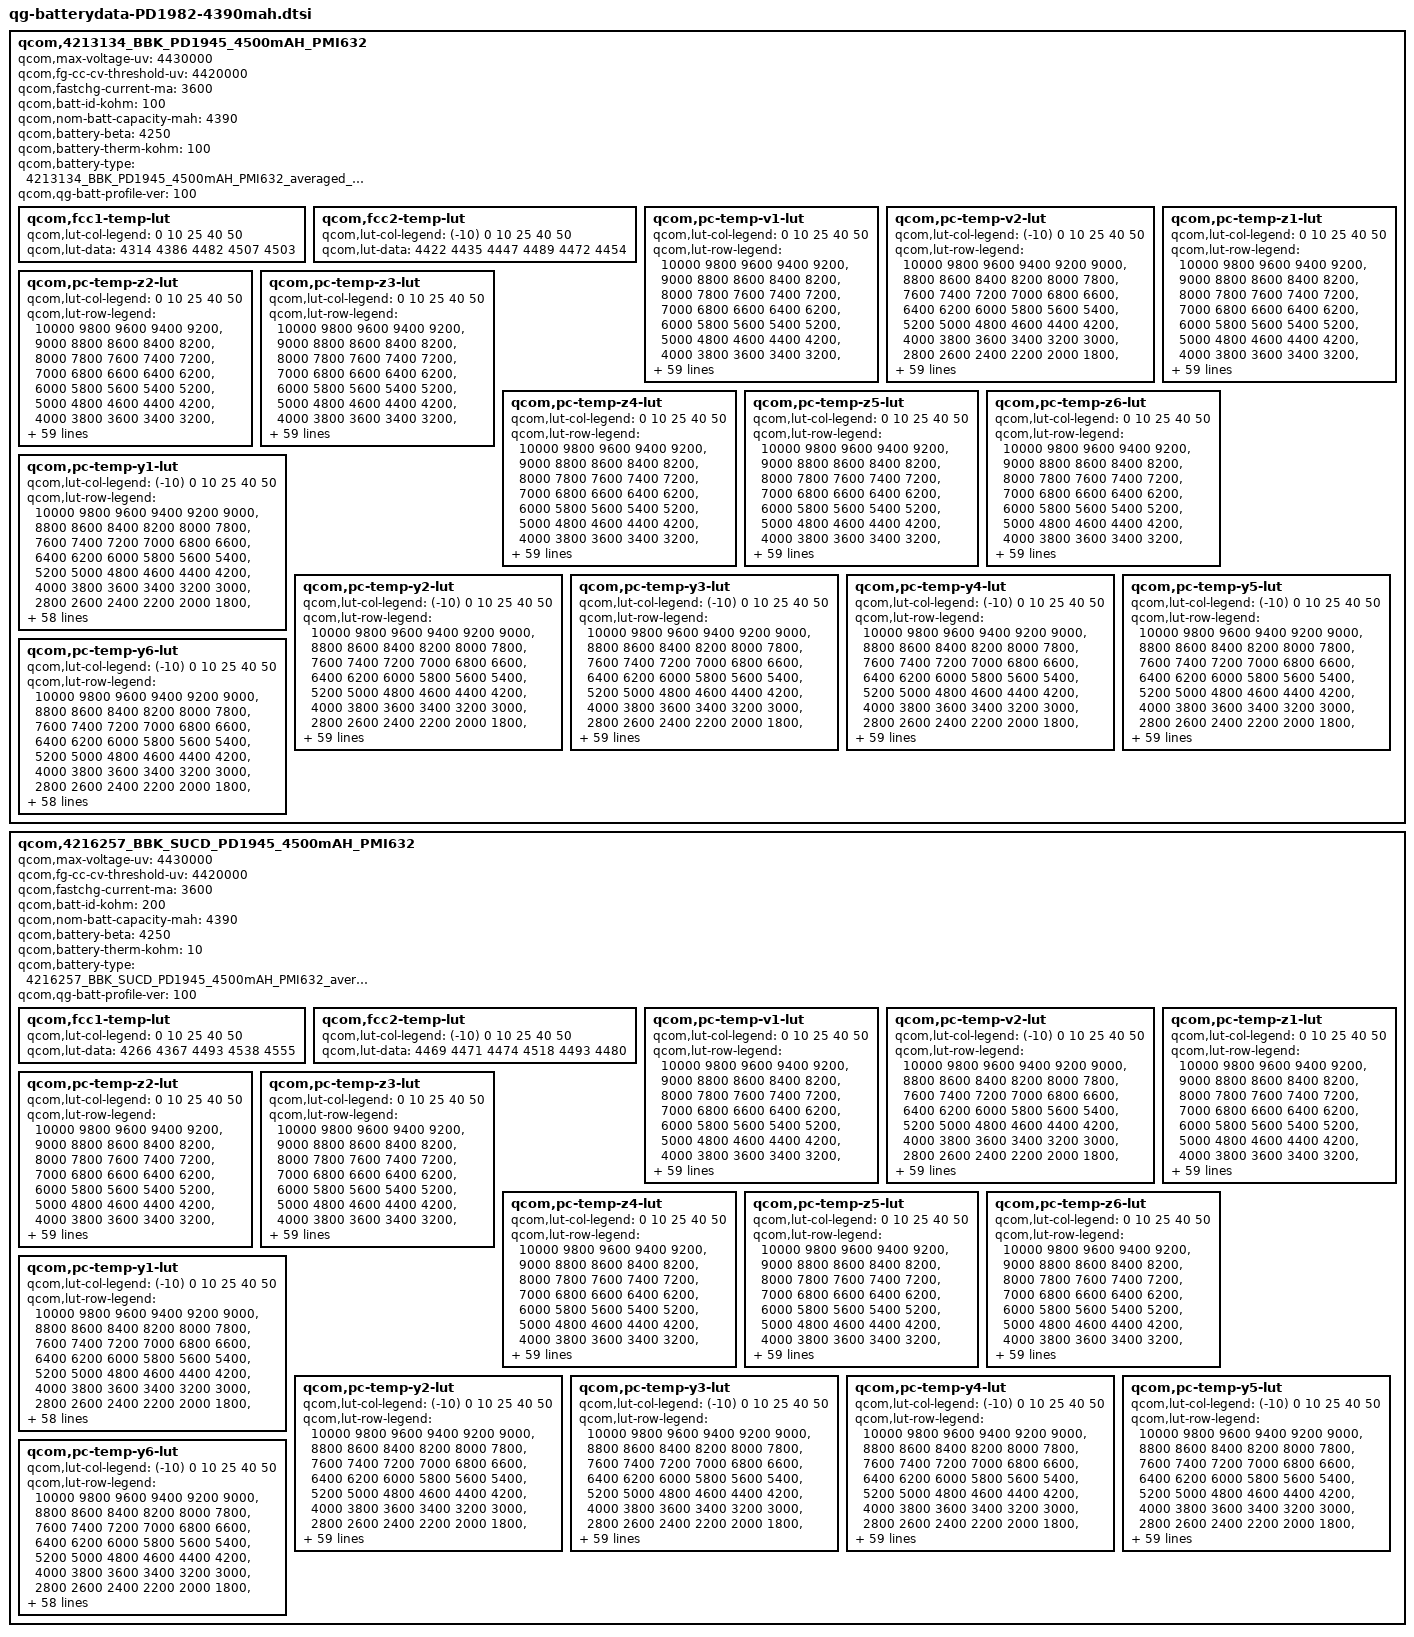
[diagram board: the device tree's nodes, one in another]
/*
 * Copyright (c) 2018, The Linux Foundation. All rights reserved.
 *
 * This program is free software; you can redistribute it and/or modify
 * it under the terms of the GNU General Public License version 2 and
 * only version 2 as published by the Free Software Foundation.
 *
 * This program is distributed in the hope that it will be useful,
 * but WITHOUT ANY WARRANTY; without even the implied warranty of
 * MERCHANTABILITY or FITNESS FOR A PARTICULAR PURPOSE.  See the
 * GNU General Public License for more details.
 */

qcom,4213134_BBK_PD1945_4500mAH_PMI632 {
    /* 4213134_BBK_PD1945_4500mAH_PMI632_averaged_MasterSlave_Sep23th2019 */
    qcom,max-voltage-uv = <4430000>;
    qcom,fg-cc-cv-threshold-uv = <4420000>;
    qcom,fastchg-current-ma = <3600>;
    qcom,batt-id-kohm = <100>;
    qcom,nom-batt-capacity-mah = <4390>;/*min value*/
    qcom,battery-beta = <4250>;
    qcom,battery-therm-kohm = <100>;
    qcom,battery-type = "4213134_BBK_PD1945_4500mAH_PMI632_averaged_MasterSlave_Sep23th2019:batid(20)";
    qcom,qg-batt-profile-ver = <100>;

	qcom,fcc1-temp-lut {
		qcom,lut-col-legend = <0 10 25 40 50>;
		qcom,lut-data = <4314 4386 4482 4507 4503>;
	};

	qcom,fcc2-temp-lut {
		qcom,lut-col-legend = <(-10) 0 10 25 40 50>;
		qcom,lut-data = <4422 4435 4447 4489 4472 4454>;
	};

	qcom,pc-temp-v1-lut {
		qcom,lut-col-legend = <0 10 25 40 50>;
		qcom,lut-row-legend = <10000 9800 9600 9400 9200>,
			<9000 8800 8600 8400 8200>,
			<8000 7800 7600 7400 7200>,
			<7000 6800 6600 6400 6200>,
			<6000 5800 5600 5400 5200>,
			<5000 4800 4600 4400 4200>,
			<4000 3800 3600 3400 3200>,
			<3000 2800 2600 2400 2200>,
			<2000 1800 1600 1400 1200>,
			<1000 900 800 700 600>,
			<500 400 300 200 100>,
			<0>;
		qcom,lut-data = <44058 44126 44178 44192 44193>,
			<43861 43942 43979 43987 44004>,
			<43646 43740 43774 43783 43799>,
			<43423 43524 43561 43575 43594>,
			<43195 43301 43340 43361 43386>,
			<42962 43069 43112 43142 43171>,
			<42728 42833 42877 42912 42944>,
			<42490 42596 42637 42675 42709>,
			<42253 42357 42397 42438 42473>,
			<42022 42119 42155 42198 42234>,
			<41793 41885 41917 41960 41997>,
			<41571 41655 41685 41725 41763>,
			<41353 41432 41458 41494 41532>,
			<41143 41215 41235 41269 41307>,
			<40939 41004 41016 41049 41086>,
			<40741 40801 40807 40836 40873>,
			<40547 40605 40604 40631 40668>,
			<40363 40419 40410 40433 40470>,
			<40182 40251 40231 40248 40283>,
			<39994 40073 40064 40079 40107>,
			<39797 39845 39881 39900 39922>,
			<39598 39578 39650 39679 39701>,
			<39396 39356 39413 39442 39469>,
			<39190 39181 39218 39240 39270>,
			<39025 39030 39047 39062 39091>,
			<38911 38903 38900 38909 38936>,
			<38817 38792 38777 38785 38806>,
			<38726 38693 38670 38678 38692>,
			<38638 38602 38570 38576 38585>,
			<38560 38520 38478 38479 38485>,
			<38496 38447 38395 38390 38393>,
			<38439 38379 38321 38309 38308>,
			<38390 38319 38254 38235 38230>,
			<38346 38268 38197 38169 38159>,
			<38307 38222 38149 38111 38096>,
			<38269 38180 38102 38053 38030>,
			<38234 38145 38058 37992 37954>,
			<38188 38103 38011 37928 37870>,
			<38109 38030 37944 37851 37781>,
			<38001 37922 37849 37758 37686>,
			<37886 37804 37740 37652 37579>,
			<37756 37676 37617 37527 37451>,
			<37603 37532 37476 37385 37308>,
			<37421 37360 37307 37222 37138>,
			<37273 37212 37172 37097 37022>,
			<37184 37126 37094 37026 36966>,
			<37161 37103 37072 37008 36946>,
			<37134 37083 37052 36993 36930>,
			<37104 37060 37035 36970 36905>,
			<37025 36981 36931 36827 36745>,
			<36709 36634 36569 36463 36375>,
			<36224 36156 36097 35986 35898>,
			<35611 35539 35484 35370 35284>,
			<34767 34693 34645 34534 34446>,
			<33365 33334 33343 33230 33147>,
			<30000 30000 30000 30000 30000>;
	};

	qcom,pc-temp-v2-lut {
		qcom,lut-col-legend = <(-10) 0 10 25 40 50>;
		qcom,lut-row-legend = <10000 9800 9600 9400 9200 9000>,
			<8800 8600 8400 8200 8000 7800>,
			<7600 7400 7200 7000 6800 6600>,
			<6400 6200 6000 5800 5600 5400>,
			<5200 5000 4800 4600 4400 4200>,
			<4000 3800 3600 3400 3200 3000>,
			<2800 2600 2400 2200 2000 1800>,
			<1600 1400 1200 1000 900 800>,
			<700 600 500 400 300 200>,
			<100 0>;
		qcom,lut-data = <44150 44150 44140 44170 44110 44100>,
			<43851 43894 43909 43937 43882 43877>,
			<43571 43647 43682 43707 43656 43654>,
			<43312 43411 43461 43483 43434 43435>,
			<43074 43188 43248 43265 43216 43219>,
			<42838 42963 43030 43042 42994 43000>,
			<42589 42727 42798 42806 42761 42769>,
			<42337 42486 42560 42565 42521 42532>,
			<42094 42248 42323 42324 42283 42296>,
			<41859 42009 42085 42082 42043 42058>,
			<41629 41774 41850 41844 41807 41823>,
			<41399 41546 41617 41609 41574 41591>,
			<41172 41323 41388 41380 41345 41363>,
			<40963 41109 41165 41154 41121 41140>,
			<40788 40904 40949 40933 40902 40921>,
			<40600 40698 40737 40720 40691 40709>,
			<40327 40485 40530 40515 40487 40505>,
			<39977 40266 40325 40316 40291 40308>,
			<39684 40030 40110 40125 40103 40119>,
			<39466 39758 39878 39944 39928 39944>,
			<39272 39493 39644 39749 39742 39761>,
			<39081 39272 39412 39503 39503 39529>,
			<38898 39079 39182 39239 39240 39267>,
			<38727 38906 38988 39035 39036 39059>,
			<38558 38751 38831 38872 38880 38904>,
			<38406 38611 38693 38730 38746 38771>,
			<38288 38486 38567 38606 38624 38648>,
			<38190 38374 38454 38495 38515 38537>,
			<38112 38268 38351 38396 38415 38434>,
			<38053 38164 38256 38304 38319 38337>,
			<38003 38070 38168 38219 38232 38247>,
			<37953 37993 38085 38139 38155 38165>,
			<37905 37928 38008 38064 38083 38090>,
			<37854 37872 37935 37991 38008 38009>,
			<37801 37826 37867 37921 37927 37919>,
			<37745 37785 37803 37849 37840 37821>,
			<37680 37734 37742 37770 37743 37715>,
			<37603 37676 37687 37685 37635 37597>,
			<37518 37607 37620 37600 37534 37488>,
			<37426 37527 37534 37517 37447 37395>,
			<37324 37429 37430 37425 37354 37303>,
			<37212 37305 37308 37313 37238 37188>,
			<37079 37136 37162 37184 37105 37053>,
			<36951 36979 37024 37022 36964 36923>,
			<36834 36846 36910 36933 36878 36827>,
			<36738 36762 36858 36902 36855 36804>,
			<36691 36728 36828 36889 36840 36789>,
			<36631 36672 36794 36868 36820 36768>,
			<36539 36584 36712 36824 36743 36706>,
			<36378 36391 36478 36640 36482 36430>,
			<36079 36005 36020 36240 36023 35994>,
			<35571 35454 35412 35695 35451 35441>,
			<34848 34726 34596 34990 34695 34722>,
			<33820 33670 33457 34017 33682 33737>,
			<32264 32252 31894 32662 32053 32492>,
			<29398 29016 29007 29006 29006 29067>;
	};

	qcom,pc-temp-z1-lut {
		qcom,lut-col-legend = <0 10 25 40 50>;
		qcom,lut-row-legend = <10000 9800 9600 9400 9200>,
			<9000 8800 8600 8400 8200>,
			<8000 7800 7600 7400 7200>,
			<7000 6800 6600 6400 6200>,
			<6000 5800 5600 5400 5200>,
			<5000 4800 4600 4400 4200>,
			<4000 3800 3600 3400 3200>,
			<3000 2800 2600 2400 2200>,
			<2000 1800 1600 1400 1200>,
			<1000 900 800 700 600>,
			<500 400 300 200 100>,
			<0>;
		qcom,lut-data = <12909 12372 11810 11693 11673>,
			<13003 12463 11919 11787 11832>,
			<13027 12490 11986 11868 11886>,
			<13036 12503 11994 11887 11895>,
			<13039 12507 11995 11889 11898>,
			<13040 12506 11996 11889 11899>,
			<13039 12505 11993 11889 11898>,
			<13027 12504 11988 11888 11897>,
			<13014 12504 11984 11888 11896>,
			<13009 12503 11981 11888 11892>,
			<13007 12490 11979 11888 11890>,
			<13005 12470 11978 11887 11892>,
			<13002 12466 11977 11884 11895>,
			<12999 12467 11978 11884 11896>,
			<13002 12468 11982 11885 11897>,
			<13021 12466 11984 11887 11898>,
			<13036 12463 11984 11889 11900>,
			<13038 12460 11983 11892 11902>,
			<13039 12454 11985 11894 11903>,
			<13039 12450 11990 11895 11905>,
			<13040 12456 11995 11897 11906>,
			<13040 12473 11999 11899 11909>,
			<13044 12483 12003 11902 11912>,
			<13054 12485 12006 11905 11913>,
			<13059 12486 12009 11907 11913>,
			<13054 12490 12013 11909 11914>,
			<13046 12497 12017 11912 11915>,
			<13045 12502 12022 11916 11917>,
			<13049 12504 12026 11920 11920>,
			<13052 12506 12030 11924 11925>,
			<13048 12508 12034 11927 11928>,
			<13039 12512 12038 11929 11928>,
			<13036 12513 12043 11930 11929>,
			<13047 12511 12048 11933 11930>,
			<13063 12507 12055 11936 11936>,
			<13082 12506 12061 11941 11941>,
			<13105 12511 12065 11946 11943>,
			<13118 12519 12068 11950 11944>,
			<13119 12533 12073 11952 11947>,
			<13120 12552 12078 11953 11950>,
			<13126 12562 12080 11954 11952>,
			<13155 12566 12080 11957 11953>,
			<13172 12570 12081 11960 11953>,
			<13177 12577 12090 11962 11954>,
			<13186 12582 12091 11963 11956>,
			<13178 12565 12092 11968 11956>,
			<13168 12561 12097 11967 11956>,
			<13137 12563 12089 11967 11958>,
			<13186 12568 12097 11970 11960>,
			<13198 12604 12107 11973 11962>,
			<13213 12609 12117 11980 11966>,
			<13242 12628 12121 11986 11973>,
			<13255 12618 12134 11988 11976>,
			<13220 12666 12143 12000 11988>,
			<13220 12666 12143 12000 11988>,
			<13220 12666 12143 12000 11988>;
	};

	qcom,pc-temp-z2-lut {
		qcom,lut-col-legend = <0 10 25 40 50>;
		qcom,lut-row-legend = <10000 9800 9600 9400 9200>,
			<9000 8800 8600 8400 8200>,
			<8000 7800 7600 7400 7200>,
			<7000 6800 6600 6400 6200>,
			<6000 5800 5600 5400 5200>,
			<5000 4800 4600 4400 4200>,
			<4000 3800 3600 3400 3200>,
			<3000 2800 2600 2400 2200>,
			<2000 1800 1600 1400 1200>,
			<1000 900 800 700 600>,
			<500 400 300 200 100>,
			<0>;
		qcom,lut-data = <10160 10683 10914 10834 10813>,
			<10473 10503 10786 10813 10723>,
			<10412 10486 10713 10734 10686>,
			<10358 10484 10717 10723 10690>,
			<10338 10484 10746 10788 10740>,
			<10324 10491 10758 10837 10776>,
			<10322 10504 10733 10783 10735>,
			<10342 10518 10704 10684 10666>,
			<10361 10535 10711 10662 10660>,
			<10364 10543 10742 10675 10719>,
			<10365 10538 10757 10691 10788>,
			<10366 10529 10755 10705 10854>,
			<10367 10523 10752 10718 10912>,
			<10368 10518 10739 10716 10908>,
			<10367 10515 10707 10684 10818>,
			<10364 10514 10691 10661 10756>,
			<10361 10514 10693 10670 10790>,
			<10361 10515 10698 10693 10846>,
			<10362 10521 10709 10718 10851>,
			<10359 10527 10733 10752 10810>,
			<10317 10524 10744 10772 10782>,
			<10274 10511 10739 10758 10785>,
			<10277 10494 10729 10727 10788>,
			<10302 10465 10706 10696 10773>,
			<10315 10439 10658 10661 10681>,
			<10298 10437 10635 10641 10618>,
			<10274 10439 10651 10642 10662>,
			<10271 10442 10678 10645 10733>,
			<10285 10448 10696 10651 10745>,
			<10301 10457 10710 10677 10732>,
			<10311 10466 10725 10707 10723>,
			<10320 10475 10741 10741 10740>,
			<10327 10483 10759 10771 10776>,
			<10333 10489 10783 10776 10811>,
			<10338 10493 10816 10769 10851>,
			<10342 10500 10832 10764 10897>,
			<10345 10511 10823 10826 10963>,
			<10349 10523 10811 10927 11032>,
			<10363 10541 10826 10946 11064>,
			<10380 10561 10901 10936 11082>,
			<10384 10567 10945 10929 11090>,
			<10382 10548 10916 10953 11074>,
			<10376 10539 10889 10993 11034>,
			<10359 10574 10932 11024 10878>,
			<10418 10605 10942 10946 10844>,
			<10392 10580 10842 10880 10977>,
			<10381 10629 10876 10921 10887>,
			<10372 10670 10865 10864 10918>,
			<10270 10870 10847 10915 11029>,
			<10210 10969 11140 10707 10712>,
			<9994 10851 10828 10646 10616>,
			<10033 10843 10902 10617 10604>,
			<9942 10694 10927 10524 10537>,
			<9789 10526 10680 10551 10455>,
			<9789 10526 10680 10551 10455>,
			<9789 10526 10680 10551 10455>;
	};

	qcom,pc-temp-z3-lut {
		qcom,lut-col-legend = <0 10 25 40 50>;
		qcom,lut-row-legend = <10000 9800 9600 9400 9200>,
			<9000 8800 8600 8400 8200>,
			<8000 7800 7600 7400 7200>,
			<7000 6800 6600 6400 6200>,
			<6000 5800 5600 5400 5200>,
			<5000 4800 4600 4400 4200>,
			<4000 3800 3600 3400 3200>,
			<3000 2800 2600 2400 2200>,
			<2000 1800 1600 1400 1200>,
			<1000 900 800 700 600>,
			<500 400 300 200 100>,
			<0>;
		qcom,lut-data = <19334 19353 19323 19280 19318>,
			<19550 19437 19356 19340 19332>,
			<19641 19488 19380 19354 19333>,
			<19679 19527 19391 19356 19334>,
			<19684 19539 19398 19356 19334>,
			<19686 19531 19400 19356 19334>,
			<19685 19519 19393 19351 19333>,
			<19671 19510 19384 19343 19332>,
			<19654 19501 19382 19340 19332>,
			<19649 19497 19381 19339 19332>,
			<19646 19497 19380 19338 19332>,
			<19643 19498 19372 19337 19332>,
			<19640 19498 19363 19337 19333>,
			<19638 19497 19363 19337 19332>,
			<19638 19496 19366 19337 19330>,
			<19645 19495 19368 19337 19327>,
			<19650 19494 19366 19336 19321>,
			<19647 19491 19363 19335 19315>,
			<19640 19478 19361 19333 19313>,
			<19638 19468 19358 19326 19314>,
			<19647 19481 19358 19321 19314>,
			<19660 19519 19374 19336 19328>,
			<19669 19538 19396 19361 19350>,
			<19678 19543 19398 19367 19354>,
			<19682 19545 19396 19367 19349>,
			<19681 19544 19395 19365 19345>,
			<19680 19538 19395 19359 19344>,
			<19679 19531 19396 19348 19343>,
			<19678 19524 19396 19345 19342>,
			<19678 19518 19393 19345 19340>,
			<19674 19513 19390 19344 19338>,
			<19665 19510 19388 19341 19335>,
			<19657 19507 19386 19337 19333>,
			<19649 19503 19383 19335 19329>,
			<19643 19501 19379 19335 19322>,
			<19642 19500 19377 19334 19318>,
			<19642 19500 19377 19331 19319>,
			<19642 19500 19377 19327 19320>,
			<19639 19498 19376 19327 19323>,
			<19633 19493 19369 19329 19326>,
			<19626 19487 19366 19331 19328>,
			<19612 19483 19366 19334 19330>,
			<19605 19476 19366 19338 19332>,
			<19603 19461 19370 19342 19338>,
			<19550 19457 19367 19338 19339>,
			<19476 19452 19353 19332 19320>,
			<19345 19435 19347 19322 19317>,
			<19341 19423 19353 19316 19313>,
			<19332 19366 19337 19314 19310>,
			<19316 19327 19322 19333 19320>,
			<19273 19339 19364 19338 19327>,
			<19333 19339 19336 19339 19331>,
			<19338 19343 19331 19342 19329>,
			<19359 19341 19361 19344 19342>,
			<19359 19341 19361 19344 19342>,
			<19359 19341 19361 19344 19342>;
	};

	qcom,pc-temp-z4-lut {
		qcom,lut-col-legend = <0 10 25 40 50>;
		qcom,lut-row-legend = <10000 9800 9600 9400 9200>,
			<9000 8800 8600 8400 8200>,
			<8000 7800 7600 7400 7200>,
			<7000 6800 6600 6400 6200>,
			<6000 5800 5600 5400 5200>,
			<5000 4800 4600 4400 4200>,
			<4000 3800 3600 3400 3200>,
			<3000 2800 2600 2400 2200>,
			<2000 1800 1600 1400 1200>,
			<1000 900 800 700 600>,
			<500 400 300 200 100>,
			<0>;
		qcom,lut-data = <15468 15168 14893 14811 14752>,
			<15498 15179 14909 14819 14775>,
			<15425 15155 14912 14815 14779>,
			<15333 15078 14899 14807 14777>,
			<15224 15010 14854 14786 14762>,
			<15105 14962 14825 14769 14749>,
			<15045 14923 14815 14765 14744>,
			<15020 14903 14808 14762 14741>,
			<15001 14890 14798 14758 14737>,
			<14982 14878 14787 14752 14732>,
			<14965 14865 14779 14746 14727>,
			<14952 14852 14776 14740 14721>,
			<14941 14842 14772 14734 14714>,
			<14933 14832 14765 14728 14710>,
			<14932 14827 14754 14721 14706>,
			<14935 14829 14746 14714 14703>,
			<14937 14834 14741 14708 14700>,
			<14934 14835 14737 14702 14697>,
			<14928 14828 14735 14699 14692>,
			<14928 14821 14734 14697 14686>,
			<14972 14876 14734 14696 14682>,
			<15033 15016 14788 14723 14706>,
			<15085 15072 14857 14769 14745>,
			<15137 15026 14863 14779 14753>,
			<15159 14963 14851 14776 14751>,
			<15113 14929 14837 14771 14748>,
			<15043 14905 14820 14767 14742>,
			<15017 14891 14803 14761 14735>,
			<15007 14883 14793 14755 14730>,
			<15002 14878 14786 14747 14725>,
			<15001 14877 14780 14740 14720>,
			<15001 14878 14776 14734 14715>,
			<15001 14878 14772 14730 14710>,
			<14996 14878 14770 14725 14705>,
			<14989 14876 14768 14719 14701>,
			<14983 14873 14768 14717 14699>,
			<14976 14867 14771 14726 14706>,
			<14968 14861 14775 14741 14718>,
			<14960 14857 14778 14743 14720>,
			<14951 14855 14780 14740 14718>,
			<14937 14849 14780 14735 14717>,
			<14911 14827 14770 14730 14714>,
			<14890 14810 14761 14726 14712>,
			<14877 14804 14761 14733 14735>,
			<14864 14776 14749 14725 14721>,
			<14913 14751 14732 14705 14686>,
			<15036 14746 14718 14698 14677>,
			<15032 14743 14695 14683 14664>,
			<15035 14795 14689 14669 14654>,
			<15050 14841 14715 14682 14678>,
			<15103 14842 14691 14684 14680>,
			<15061 14845 14714 14682 14678>,
			<15068 14847 14718 14680 14678>,
			<15081 14865 14689 14675 14665>,
			<15081 14865 14689 14675 14665>,
			<15081 14865 14689 14675 14665>;
	};

	qcom,pc-temp-z5-lut {
		qcom,lut-col-legend = <0 10 25 40 50>;
		qcom,lut-row-legend = <10000 9800 9600 9400 9200>,
			<9000 8800 8600 8400 8200>,
			<8000 7800 7600 7400 7200>,
			<7000 6800 6600 6400 6200>,
			<6000 5800 5600 5400 5200>,
			<5000 4800 4600 4400 4200>,
			<4000 3800 3600 3400 3200>,
			<3000 2800 2600 2400 2200>,
			<2000 1800 1600 1400 1200>,
			<1000 900 800 700 600>,
			<500 400 300 200 100>,
			<0>;
		qcom,lut-data = <11380 12222 13042 12588 15854>,
			<13715 13976 14666 16365 16786>,
			<15239 15613 16038 17797 17456>,
			<16325 17177 17213 18535 17905>,
			<17190 17874 18277 19083 18268>,
			<17848 18038 18631 19327 18435>,
			<18000 18123 18126 18777 18432>,
			<17902 18068 17544 17770 18426>,
			<17807 17817 17556 17529 18473>,
			<17887 17669 17791 17579 18809>,
			<18184 17939 17886 17653 19213>,
			<18465 18426 17261 17735 19622>,
			<18639 18758 16520 17846 19992>,
			<18819 19032 16616 18007 20034>,
			<19174 19173 17238 18272 19817>,
			<19895 19109 17544 18576 19475>,
			<20366 18924 17479 18951 18655>,
			<20086 18651 17400 19313 17641>,
			<19508 18033 17434 19216 17491>,
			<19439 17544 17596 18123 17885>,
			<21150 18238 17696 17332 18449>,
			<22912 20075 17720 18026 19411>,
			<22246 20795 17732 19232 20471>,
			<19584 19960 17542 19395 20365>,
			<18153 19023 16813 18632 18562>,
			<18573 19149 16426 17829 17330>,
			<19432 20041 16993 17288 17579>,
			<20477 20854 17960 16867 18112>,
			<22112 21340 18693 16903 18606>,
			<23196 21760 19328 17633 19112>,
			<23246 22222 19991 18333 19618>,
			<23262 22749 20784 18602 20210>,
			<23241 23082 21554 18818 20727>,
			<22830 23161 22101 19345 20801>,
			<22382 23208 22544 20629 20690>,
			<22396 23321 22809 21425 20542>,
			<22658 23624 22945 20621 20333>,
			<22965 23942 23028 19301 20121>,
			<23347 24165 22807 19089 20281>,
			<23711 24352 21757 19526 21477>,
			<23483 24359 21126 20131 22677>,
			<21617 23514 21177 21085 23283>,
			<20781 22144 21280 21775 23900>,
			<20673 19763 21497 21724 25207>,
			<17543 20153 20709 20575 25273>,
			<15379 20017 18768 19367 19017>,
			<11754 17986 18594 17961 18983>,
			<11672 16937 21314 18297 20510>,
			<11562 13627 18543 19715 22576>,
			<11424 12462 15384 21133 19999>,
			<11118 12639 20548 20437 20695>,
			<11453 12541 15538 19859 20789>,
			<11425 12534 14807 19820 19272>,
			<11607 12381 17927 19108 21806>,
			<11607 12381 17927 19108 21806>,
			<11607 12381 17927 19108 21806>;
	};

	qcom,pc-temp-z6-lut {
		qcom,lut-col-legend = <0 10 25 40 50>;
		qcom,lut-row-legend = <10000 9800 9600 9400 9200>,
			<9000 8800 8600 8400 8200>,
			<8000 7800 7600 7400 7200>,
			<7000 6800 6600 6400 6200>,
			<6000 5800 5600 5400 5200>,
			<5000 4800 4600 4400 4200>,
			<4000 3800 3600 3400 3200>,
			<3000 2800 2600 2400 2200>,
			<2000 1800 1600 1400 1200>,
			<1000 900 800 700 600>,
			<500 400 300 200 100>,
			<0>;
		qcom,lut-data = <15431 15023 14709 14631 14620>,
			<15514 15080 14753 14684 14664>,
			<15503 15079 14776 14699 14676>,
			<15484 15062 14774 14700 14676>,
			<15436 15041 14761 14692 14670>,
			<15360 15012 14748 14684 14664>,
			<15313 14982 14739 14678 14662>,
			<15286 14963 14732 14673 14660>,
			<15266 14950 14726 14669 14658>,
			<15250 14940 14720 14666 14656>,
			<15236 14931 14715 14663 14654>,
			<15226 14924 14709 14660 14652>,
			<15217 14917 14704 14657 14649>,
			<15210 14911 14700 14655 14647>,
			<15209 14908 14698 14652 14644>,
			<15212 14908 14695 14649 14641>,
			<15213 14907 14692 14646 14637>,
			<15210 14906 14689 14644 14633>,
			<15204 14897 14688 14641 14630>,
			<15203 14889 14687 14637 14628>,
			<15228 14921 14687 14635 14627>,
			<15263 15003 14720 14655 14645>,
			<15294 15037 14762 14689 14675>,
			<15327 15021 14766 14697 14681>,
			<15341 14998 14761 14696 14678>,
			<15322 14983 14755 14694 14675>,
			<15295 14972 14749 14689 14672>,
			<15288 14964 14743 14682 14668>,
			<15287 14958 14738 14677 14665>,
			<15286 14954 14734 14674 14663>,
			<15285 14954 14731 14671 14660>,
			<15284 14955 14729 14667 14656>,
			<15283 14955 14727 14663 14653>,
			<15280 14955 14726 14660 14648>,
			<15278 14955 14724 14657 14643>,
			<15279 14956 14723 14656 14640>,
			<15284 14957 14726 14659 14644>,
			<15287 14958 14729 14665 14650>,
			<15289 14958 14729 14666 14653>,
			<15290 14957 14729 14666 14654>,
			<15289 14956 14727 14665 14655>,
			<15280 14948 14723 14665 14655>,
			<15278 14941 14720 14666 14655>,
			<15281 14936 14724 14671 14669>,
			<15262 14926 14718 14666 14664>,
			<15251 14916 14703 14654 14639>,
			<15241 14908 14695 14646 14633>,
			<15241 14903 14688 14637 14626>,
			<15244 14900 14678 14630 14619>,
			<15254 14905 14684 14646 14636>,
			<15269 14917 14696 14651 14642>,
			<15288 14925 14694 14653 14645>,
			<15310 14936 14696 14654 14645>,
			<15350 14956 14703 14656 14649>,
			<15350 14956 14703 14656 14649>,
			<15350 14956 14703 14656 14649>;
	};

	qcom,pc-temp-y1-lut {
		qcom,lut-col-legend = <(-10) 0 10 25 40 50>;
		qcom,lut-row-legend = <10000 9800 9600 9400 9200 9000>,
			<8800 8600 8400 8200 8000 7800>,
			<7600 7400 7200 7000 6800 6600>,
			<6400 6200 6000 5800 5600 5400>,
			<5200 5000 4800 4600 4400 4200>,
			<4000 3800 3600 3400 3200 3000>,
			<2800 2600 2400 2200 2000 1800>,
			<1600 1400 1200 1000 900 800>,
			<700 600 500 400 300 200>,
			<100 0>;
		qcom,lut-data = <6485 6077 5817 5476 5385 5393>,
			<6507 6079 5808 5470 5386 5392>,
			<6524 6080 5799 5464 5386 5391>,
			<6537 6081 5790 5459 5387 5390>,
			<6545 6081 5782 5454 5387 5388>,
			<6548 6081 5775 5451 5387 5388>,
			<6543 6078 5768 5447 5385 5388>,
			<6535 6070 5762 5445 5382 5388>,
			<6533 6063 5757 5443 5380 5388>,
			<6538 6053 5755 5441 5379 5387>,
			<6543 6048 5752 5440 5378 5386>,
			<6538 6051 5748 5438 5377 5386>,
			<6528 6059 5741 5438 5377 5386>,
			<6524 6063 5736 5437 5376 5386>,
			<6528 6066 5732 5436 5376 5386>,
			<6533 6067 5729 5435 5375 5385>,
			<6537 6063 5726 5437 5376 5386>,
			<6542 6054 5724 5440 5377 5387>,
			<6544 6051 5723 5440 5378 5387>,
			<6541 6053 5723 5438 5378 5386>,
			<6538 6055 5723 5437 5379 5385>,
			<6537 6056 5723 5438 5380 5387>,
			<6537 6055 5723 5439 5381 5390>,
			<6537 6055 5723 5441 5383 5391>,
			<6536 6054 5725 5444 5384 5391>,
			<6534 6053 5729 5447 5385 5391>,
			<6534 6054 5733 5450 5386 5391>,
			<6533 6059 5737 5454 5386 5391>,
			<6533 6066 5739 5456 5387 5391>,
			<6534 6074 5740 5458 5388 5393>,
			<6534 6082 5740 5459 5389 5396>,
			<6538 6080 5741 5461 5391 5396>,
			<6559 6070 5745 5463 5393 5396>,
			<6574 6064 5749 5466 5395 5396>,
			<6561 6066 5752 5469 5395 5399>,
			<6539 6068 5755 5472 5396 5403>,
			<6533 6069 5755 5475 5397 5404>,
			<6538 6070 5753 5477 5399 5405>,
			<6542 6072 5752 5479 5401 5406>,
			<6539 6074 5752 5481 5403 5407>,
			<6531 6077 5753 5482 5405 5408>,
			<6529 6080 5756 5484 5406 5409>,
			<6532 6082 5764 5486 5406 5409>,
			<6534 6079 5771 5490 5408 5410>,
			<6530 6066 5778 5493 5411 5411>,
			<6555 6089 5789 5496 5412 5412>,
			<6593 6091 5789 5500 5412 5413>,
			<6603 6084 5793 5497 5412 5417>,
			<6589 6094 5799 5497 5415 5414>,
			<6624 6112 5809 5498 5415 5416>,
			<6681 6116 5814 5501 5415 5419>,
			<6716 6135 5828 5509 5419 5419>,
			<6822 6192 5841 5513 5422 5425>,
			<7386 6354 5859 5524 5430 5433>,
			<7386 6354 5859 5524 5430 5433>,
			<7386 6354 5859 5524 5430 5433>;
	};

	qcom,pc-temp-y2-lut {
		qcom,lut-col-legend = <(-10) 0 10 25 40 50>;
		qcom,lut-row-legend = <10000 9800 9600 9400 9200 9000>,
			<8800 8600 8400 8200 8000 7800>,
			<7600 7400 7200 7000 6800 6600>,
			<6400 6200 6000 5800 5600 5400>,
			<5200 5000 4800 4600 4400 4200>,
			<4000 3800 3600 3400 3200 3000>,
			<2800 2600 2400 2200 2000 1800>,
			<1600 1400 1200 1000 900 800>,
			<700 600 500 400 300 200>,
			<100 0>;
		qcom,lut-data = <10559 10993 11178 11698 11550 11333>,
			<10584 10978 11160 11632 11498 11376>,
			<10618 10950 11144 11543 11448 11403>,
			<10653 10917 11127 11452 11403 11417>,
			<10680 10889 11110 11382 11361 11422>,
			<10693 10876 11094 11353 11325 11422>,
			<10689 10874 11077 11363 11293 11408>,
			<10683 10874 11060 11379 11265 11374>,
			<10682 10872 11047 11373 11249 11337>,
			<10694 10869 11036 11320 11240 11287>,
			<10712 10867 11030 11284 11233 11256>,
			<10732 10872 11032 11286 11223 11271>,
			<10757 10885 11039 11290 11215 11301>,
			<10785 10903 11046 11288 11216 11306>,
			<10822 10938 11055 11269 11236 11275>,
			<10849 10973 11068 11256 11251 11249>,
			<10849 10993 11116 11270 11236 11251>,
			<10843 11008 11196 11304 11209 11259>,
			<10841 11018 11220 11351 11212 11270>,
			<10841 11024 11182 11432 11294 11293>,
			<10841 11030 11147 11480 11374 11321>,
			<10839 11044 11159 11465 11401 11341>,
			<10835 11069 11204 11439 11418 11359>,
			<10824 11092 11253 11449 11448 11391>,
			<10621 11118 11320 11548 11513 11473>,
			<10297 11138 11371 11619 11558 11571>,
			<10064 11139 11372 11604 11547 11653>,
			<9856 11136 11363 11577 11522 11731>,
			<9749 11134 11351 11572 11527 11765>,
			<9733 11151 11334 11579 11667 11772>,
			<9723 11176 11316 11589 11791 11778>,
			<9711 11186 11297 11615 11798 11796>,
			<9697 11191 11278 11648 11799 11828>,
			<9686 11193 11270 11652 11794 11839>,
			<9680 10952 11282 11619 11733 11772>,
			<9675 10522 11297 11576 11657 11696>,
			<9671 10230 11294 11526 11610 11693>,
			<9667 9987 11271 11476 11572 11714>,
			<9663 9869 11244 11475 11565 11725>,
			<9661 10054 11218 11547 11613 11711>,
			<9659 10371 11186 11602 11661 11682>,
			<9658 10381 11132 11566 11645 11637>,
			<9657 9946 11036 11510 11596 11561>,
			<9656 9745 10924 11494 11560 11503>,
			<9655 9701 10792 11477 11514 11454>,
			<9654 9677 10655 11560 11426 11394>,
			<9653 9671 10620 11375 11337 11358>,
			<9653 9666 10589 11416 11295 11293>,
			<9652 9662 10512 11394 11329 11288>,
			<9651 9658 10417 11322 11301 11294>,
			<9650 9655 10265 11327 11248 11139>,
			<9649 9652 10100 11271 11215 11121>,
			<9649 9656 9731 11166 11063 11000>,
			<9649 9665 9708 10969 10837 10829>,
			<9649 9665 9708 10969 10837 10829>,
			<9649 9665 9708 10969 10837 10829>;
	};

	qcom,pc-temp-y3-lut {
		qcom,lut-col-legend = <(-10) 0 10 25 40 50>;
		qcom,lut-row-legend = <10000 9800 9600 9400 9200 9000>,
			<8800 8600 8400 8200 8000 7800>,
			<7600 7400 7200 7000 6800 6600>,
			<6400 6200 6000 5800 5600 5400>,
			<5200 5000 4800 4600 4400 4200>,
			<4000 3800 3600 3400 3200 3000>,
			<2800 2600 2400 2200 2000 1800>,
			<1600 1400 1200 1000 900 800>,
			<700 600 500 400 300 200>,
			<100 0>;
		qcom,lut-data = <13440 13354 13312 13280 13271 13273>,
			<13448 13359 13314 13280 13272 13273>,
			<13457 13364 13317 13280 13273 13273>,
			<13466 13369 13320 13280 13275 13273>,
			<13473 13373 13322 13280 13276 13273>,
			<13478 13376 13324 13280 13277 13273>,
			<13481 13378 13324 13280 13277 13274>,
			<13483 13379 13324 13280 13277 13275>,
			<13483 13380 13325 13280 13277 13276>,
			<13483 13381 13326 13281 13277 13276>,
			<13482 13382 13326 13283 13277 13276>,
			<13479 13382 13326 13285 13277 13276>,
			<13474 13383 13325 13287 13277 13276>,
			<13467 13383 13325 13288 13277 13276>,
			<13456 13381 13327 13287 13277 13276>,
			<13443 13379 13329 13287 13277 13276>,
			<13435 13375 13329 13290 13278 13276>,
			<13427 13370 13329 13295 13280 13277>,
			<13421 13364 13329 13297 13283 13278>,
			<13416 13357 13326 13298 13285 13279>,
			<13411 13351 13322 13298 13287 13281>,
			<13406 13347 13318 13295 13284 13279>,
			<13401 13343 13313 13289 13278 13274>,
			<13394 13340 13308 13284 13275 13272>,
			<13365 13335 13302 13279 13274 13272>,
			<13332 13331 13297 13277 13273 13273>,
			<13328 13330 13297 13277 13273 13273>,
			<13330 13331 13299 13278 13274 13273>,
			<13334 13331 13301 13279 13274 13273>,
			<13343 13324 13305 13282 13274 13273>,
			<13357 13315 13308 13284 13273 13272>,
			<13370 13311 13308 13284 13274 13272>,
			<13382 13310 13308 13283 13275 13271>,
			<13398 13308 13307 13283 13275 13271>,
			<13422 13304 13304 13282 13273 13271>,
			<13455 13300 13301 13281 13272 13271>,
			<13497 13301 13300 13280 13272 13271>,
			<13555 13305 13301 13279 13273 13272>,
			<13628 13313 13302 13279 13273 13272>,
			<13722 13333 13300 13279 13274 13272>,
			<13846 13360 13298 13278 13274 13272>,
			<13992 13373 13299 13279 13275 13272>,
			<14173 13378 13305 13279 13275 13273>,
			<14402 13394 13312 13279 13275 13273>,
			<14712 13453 13321 13279 13276 13272>,
			<15151 13538 13332 13277 13277 13276>,
			<15383 13589 13332 13281 13280 13277>,
			<15666 13665 13343 13288 13283 13279>,
			<16068 13805 13354 13292 13283 13280>,
			<16781 14018 13368 13289 13280 13275>,
			<18581 14414 13384 13289 13279 13277>,
			<22612 15445 13426 13290 13281 13279>,
			<32037 17786 13571 13293 13283 13282>,
			<61170 24283 14402 13299 13287 13284>,
			<61170 24283 14402 13299 13287 13284>,
			<61170 24283 14402 13299 13287 13284>;
	};

	qcom,pc-temp-y4-lut {
		qcom,lut-col-legend = <(-10) 0 10 25 40 50>;
		qcom,lut-row-legend = <10000 9800 9600 9400 9200 9000>,
			<8800 8600 8400 8200 8000 7800>,
			<7600 7400 7200 7000 6800 6600>,
			<6400 6200 6000 5800 5600 5400>,
			<5200 5000 4800 4600 4400 4200>,
			<4000 3800 3600 3400 3200 3000>,
			<2800 2600 2400 2200 2000 1800>,
			<1600 1400 1200 1000 900 800>,
			<700 600 500 400 300 200>,
			<100 0>;
		qcom,lut-data = <16838 16663 16574 16488 16472 16452>,
			<16919 16716 16590 16486 16466 16452>,
			<17034 16770 16602 16485 16462 16452>,
			<17153 16816 16608 16485 16458 16452>,
			<17249 16850 16611 16486 16456 16452>,
			<17292 16863 16612 16487 16455 16452>,
			<17283 16855 16608 16489 16456 16452>,
			<17263 16839 16601 16491 16458 16452>,
			<17259 16827 16599 16493 16461 16451>,
			<17270 16819 16599 16496 16463 16452>,
			<17288 16815 16598 16498 16466 16454>,
			<17312 16823 16603 16501 16469 16456>,
			<17349 16847 16617 16504 16473 16459>,
			<17406 16881 16632 16509 16478 16463>,
			<17542 16941 16652 16520 16483 16467>,
			<17655 17002 16677 16531 16489 16472>,
			<17551 17043 16726 16541 16494 16477>,
			<17235 17077 16790 16551 16501 16482>,
			<17053 17080 16809 16574 16513 16491>,
			<17005 16955 16789 16627 16540 16509>,
			<16970 16801 16755 16661 16558 16523>,
			<16915 16731 16694 16620 16539 16512>,
			<16847 16684 16600 16544 16498 16483>,
			<16815 16656 16558 16509 16478 16467>,
			<16811 16640 16550 16492 16470 16461>,
			<16809 16628 16545 16485 16466 16458>,
			<16805 16618 16541 16485 16466 16458>,
			<16800 16608 16538 16485 16467 16458>,
			<16797 16604 16537 16486 16469 16459>,
			<16799 16603 16537 16490 16472 16463>,
			<16804 16603 16537 16496 16476 16469>,
			<16813 16603 16537 16504 16484 16475>,
			<16831 16602 16539 16513 16494 16482>,
			<16851 16601 16541 16515 16497 16485>,
			<16867 16622 16536 16515 16495 16482>,
			<16882 16660 16529 16515 16492 16476>,
			<16897 16691 16527 16503 16484 16470>,
			<16913 16720 16526 16480 16471 16463>,
			<16928 16735 16526 16472 16465 16461>,
			<16944 16723 16530 16469 16465 16462>,
			<16959 16702 16538 16467 16464 16464>,
			<16972 16702 16548 16469 16463 16465>,
			<16980 16737 16561 16472 16462 16464>,
			<16998 16770 16575 16465 16450 16457>,
			<17061 16797 16593 16465 16442 16442>,
			<17175 16884 16642 16485 16460 16455>,
			<17184 16904 16649 16495 16475 16476>,
			<17200 16962 16692 16505 16529 16533>,
			<17297 17083 16752 16555 16547 16580>,
			<17480 17198 16776 16524 16490 16472>,
			<18096 17316 16780 16498 16467 16465>,
			<20050 17624 16864 16509 16478 16476>,
			<29894 19699 17110 16543 16504 16503>,
			<65535 34577 17512 16641 16651 16604>,
			<65535 34577 17512 16641 16651 16604>,
			<65535 34577 17512 16641 16651 16604>;
	};

	qcom,pc-temp-y5-lut {
		qcom,lut-col-legend = <(-10) 0 10 25 40 50>;
		qcom,lut-row-legend = <10000 9800 9600 9400 9200 9000>,
			<8800 8600 8400 8200 8000 7800>,
			<7600 7400 7200 7000 6800 6600>,
			<6400 6200 6000 5800 5600 5400>,
			<5200 5000 4800 4600 4400 4200>,
			<4000 3800 3600 3400 3200 3000>,
			<2800 2600 2400 2200 2000 1800>,
			<1600 1400 1200 1000 900 800>,
			<700 600 500 400 300 200>,
			<100 0>;
		qcom,lut-data = <13653 15204 14687 15773 13152 20483>,
			<13923 15406 15285 15367 14709 19326>,
			<14317 15641 15742 14980 15841 18387>,
			<14741 15866 16064 14620 16596 17685>,
			<15099 16038 16256 14297 17018 17241>,
			<15297 16112 16323 14020 17153 17079>,
			<15354 16095 16231 13746 16886 17330>,
			<15388 16046 16021 13529 16319 17766>,
			<15378 15957 15826 13495 15816 17833>,
			<15194 15706 15645 13516 15320 17515>,
			<14900 15379 15414 13553 14884 17055>,
			<14396 15037 14967 13744 14558 16471>,
			<13714 14650 14385 14014 14282 15752>,
			<13553 14276 14089 14002 14015 15189>,
			<14349 13846 13935 13605 13722 14681>,
			<15210 13568 13860 13332 13562 14396>,
			<15415 14007 13894 13638 13713 14391>,
			<15502 15197 14020 14232 14080 14398>,
			<15645 15888 14309 14591 14438 14422>,
			<16044 16174 15661 14783 14826 14603>,
			<16410 16334 16873 15034 15175 14865>,
			<16435 16363 16909 15808 15421 15106>,
			<16378 16377 16798 16779 15624 15387>,
			<16249 16365 16567 16808 15826 15807>,
			<14439 15908 15419 15699 16035 16698>,
			<12018 15374 14299 14900 16218 17508>,
			<11288 15401 14344 14933 16375 17767>,
			<10988 15703 14851 15045 16507 17919>,
			<10879 15849 15545 15487 16509 17940>,
			<10970 14945 16945 17403 16203 17479>,
			<11123 13625 18274 18770 15931 16791>,
			<11189 13107 18556 18660 16199 16186>,
			<11212 12878 18663 18411 16824 15563>,
			<11243 12644 18679 18245 17010 15348>,
			<11382 12260 17691 18134 16725 15871>,
			<11578 11892 16440 18040 16460 16730>,
			<11614 11766 16255 17966 16744 17578>,
			<11507 11712 16250 17896 17551 18551>,
			<11419 11691 16235 17773 18146 18948>,
			<11434 12975 15374 17529 18574 18568>,
			<11472 15185 14183 17211 18828 18089>,
			<11482 15304 14072 16716 18749 18536>,
			<11439 12724 14554 16312 18565 20194>,
			<11339 11890 15158 17146 20428 20242>,
			<11054 11906 15700 17106 21712 19755>,
			<11053 11634 15374 14418 17789 20057>,
			<11165 11758 15042 15302 18597 19571>,
			<11343 11644 15304 17020 18627 17284>,
			<11386 11711 14999 17290 16486 15727>,
			<11243 11668 15251 16679 16876 17238>,
			<10453 11369 14854 18071 18344 19065>,
			<9608 10825 13835 17594 18344 19101>,
			<9044 9771 11740 17767 18177 19584>,
			<8829 9009 11270 17728 18258 18689>,
			<8829 9009 11270 17728 18258 18689>,
			<8829 9009 11270 17728 18258 18689>;
	};

	qcom,pc-temp-y6-lut {
		qcom,lut-col-legend = <(-10) 0 10 25 40 50>;
		qcom,lut-row-legend = <10000 9800 9600 9400 9200 9000>,
			<8800 8600 8400 8200 8000 7800>,
			<7600 7400 7200 7000 6800 6600>,
			<6400 6200 6000 5800 5600 5400>,
			<5200 5000 4800 4600 4400 4200>,
			<4000 3800 3600 3400 3200 3000>,
			<2800 2600 2400 2200 2000 1800>,
			<1600 1400 1200 1000 900 800>,
			<700 600 500 400 300 200>,
			<100 0>;
		qcom,lut-data = <5735 5372 5184 5056 5033 5032>,
			<5777 5386 5188 5055 5033 5032>,
			<5805 5394 5189 5054 5034 5032>,
			<5822 5399 5188 5054 5034 5032>,
			<5831 5400 5187 5054 5035 5032>,
			<5834 5401 5184 5054 5035 5032>,
			<5826 5395 5181 5054 5036 5032>,
			<5810 5384 5176 5055 5036 5033>,
			<5801 5375 5172 5055 5037 5034>,
			<5796 5368 5169 5056 5037 5034>,
			<5794 5363 5168 5058 5038 5035>,
			<5794 5364 5169 5060 5039 5035>,
			<5796 5368 5170 5062 5040 5036>,
			<5800 5373 5172 5064 5041 5037>,
			<5828 5387 5177 5067 5043 5038>,
			<5854 5401 5185 5070 5045 5040>,
			<5823 5408 5199 5074 5047 5041>,
			<5731 5413 5216 5081 5050 5043>,
			<5678 5412 5221 5090 5055 5047>,
			<5663 5373 5214 5105 5065 5053>,
			<5652 5324 5200 5115 5072 5058>,
			<5640 5301 5180 5101 5064 5053>,
			<5627 5286 5151 5074 5048 5041>,
			<5615 5277 5135 5061 5040 5035>,
			<5601 5271 5128 5053 5036 5034>,
			<5591 5267 5125 5050 5035 5033>,
			<5592 5267 5125 5050 5035 5033>,
			<5601 5268 5126 5051 5035 5033>,
			<5614 5269 5128 5052 5036 5034>,
			<5634 5268 5131 5055 5037 5035>,
			<5661 5267 5134 5059 5038 5036>,
			<5692 5267 5137 5062 5041 5037>,
			<5727 5270 5139 5064 5045 5039>,
			<5769 5276 5139 5065 5046 5040>,
			<5819 5284 5137 5065 5044 5039>,
			<5879 5297 5135 5064 5043 5037>,
			<5945 5312 5135 5060 5040 5036>,
			<6018 5330 5137 5054 5037 5035>,
			<6102 5354 5139 5051 5036 5034>,
			<6199 5386 5141 5051 5037 5035>,
			<6311 5429 5144 5051 5037 5036>,
			<6441 5472 5151 5052 5037 5036>,
			<6592 5517 5163 5053 5037 5037>,
			<6784 5581 5178 5052 5034 5035>,
			<7049 5683 5197 5052 5032 5030>,
			<7436 5834 5231 5057 5039 5037>,
			<7627 5902 5236 5063 5045 5043>,
			<7851 6007 5265 5070 5063 5061>,
			<8190 6177 5303 5088 5068 5076>,
			<8816 6403 5339 5077 5050 5042>,
			<10394 6774 5380 5070 5043 5041>,
			<13896 7672 5500 5075 5048 5046>,
			<23355 10171 5777 5089 5058 5057>,
			<55975 18918 6695 5123 5104 5089>,
			<55975 18918 6695 5123 5104 5089>,
			<55975 18918 6695 5123 5104 5089>;
	};

};

qcom,4216257_BBK_SUCD_PD1945_4500mAH_PMI632 {
    /* 4055245_BBK_PD1928(TD19014216257_BBK_SUCD_PD1945_4500mAH_PMI632_averaged_MasterSlave_Sep26th2019_LW_5000mAH_PMI632_averaged_MasterSlave_Jun18th2019 */
    qcom,max-voltage-uv = <4430000>;
    qcom,fg-cc-cv-threshold-uv = <4420000>;
    qcom,fastchg-current-ma = <3600>;
    qcom,batt-id-kohm = <200>;
    qcom,nom-batt-capacity-mah = <4390>;/*min value*/
    qcom,battery-beta = <4250>;
    qcom,battery-therm-kohm = <10>;
    qcom,battery-type = "4216257_BBK_SUCD_PD1945_4500mAH_PMI632_averaged_MasterSlave_Sep26th2019:batid(200)";
    qcom,qg-batt-profile-ver = <100>;

	qcom,fcc1-temp-lut {
		qcom,lut-col-legend = <0 10 25 40 50>;
		qcom,lut-data = <4266 4367 4493 4538 4555>;
	};

	qcom,fcc2-temp-lut {
		qcom,lut-col-legend = <(-10) 0 10 25 40 50>;
		qcom,lut-data = <4469 4471 4474 4518 4493 4480>;
	};

	qcom,pc-temp-v1-lut {
		qcom,lut-col-legend = <0 10 25 40 50>;
		qcom,lut-row-legend = <10000 9800 9600 9400 9200>,
			<9000 8800 8600 8400 8200>,
			<8000 7800 7600 7400 7200>,
			<7000 6800 6600 6400 6200>,
			<6000 5800 5600 5400 5200>,
			<5000 4800 4600 4400 4200>,
			<4000 3800 3600 3400 3200>,
			<3000 2800 2600 2400 2200>,
			<2000 1800 1600 1400 1200>,
			<1000 900 800 700 600>,
			<500 400 300 200 100>,
			<0>;
		qcom,lut-data = <43917 44050 44158 44198 44204>,
			<43717 43878 43967 44005 44014>,
			<43506 43664 43766 43809 43822>,
			<43283 43423 43554 43605 43623>,
			<43046 43183 43330 43390 43411>,
			<42804 42941 43097 43166 43190>,
			<42562 42699 42856 42931 42960>,
			<42318 42458 42611 42687 42723>,
			<42081 42219 42368 42443 42482>,
			<41853 41985 42126 42201 42240>,
			<41630 41755 41887 41961 41997>,
			<41413 41531 41651 41723 41758>,
			<41200 41312 41419 41487 41521>,
			<40993 41100 41196 41255 41289>,
			<40789 40892 40980 41031 41065>,
			<40589 40688 40770 40812 40846>,
			<40396 40489 40563 40603 40634>,
			<40211 40302 40361 40400 40428>,
			<40032 40129 40177 40209 40232>,
			<39858 39943 40010 40035 40052>,
			<39692 39701 39826 39857 39873>,
			<39515 39437 39581 39632 39657>,
			<39296 39241 39324 39375 39406>,
			<39070 39098 39135 39164 39191>,
			<38921 38978 38988 39000 39022>,
			<38821 38868 38861 38858 38874>,
			<38742 38771 38745 38731 38741>,
			<38677 38682 38643 38618 38622>,
			<38622 38601 38550 38516 38513>,
			<38568 38527 38465 38424 38411>,
			<38510 38463 38391 38341 38319>,
			<38453 38405 38323 38265 38236>,
			<38405 38354 38263 38196 38160>,
			<38364 38308 38210 38135 38092>,
			<38325 38267 38166 38086 38036>,
			<38290 38229 38121 38036 37979>,
			<38256 38196 38074 37975 37909>,
			<38211 38156 38024 37907 37829>,
			<38137 38078 37955 37830 37745>,
			<38041 37963 37858 37742 37656>,
			<37934 37851 37749 37643 37557>,
			<37806 37747 37632 37526 37442>,
			<37660 37620 37499 37391 37310>,
			<37492 37444 37334 37232 37151>,
			<37335 37284 37187 37090 37015>,
			<37236 37181 37089 36998 36930>,
			<37200 37150 37059 36976 36904>,
			<37168 37125 37039 36956 36886>,
			<37137 37095 37022 36938 36869>,
			<37070 37039 36976 36881 36795>,
			<36829 36785 36708 36594 36492>,
			<36375 36338 36278 36160 36054>,
			<35801 35764 35713 35592 35486>,
			<35028 34990 34947 34824 34716>,
			<33807 33779 33766 33641 33528>,
			<30000 30000 30000 30000 30000>;
	};

	qcom,pc-temp-v2-lut {
		qcom,lut-col-legend = <(-10) 0 10 25 40 50>;
		qcom,lut-row-legend = <10000 9800 9600 9400 9200 9000>,
			<8800 8600 8400 8200 8000 7800>,
			<7600 7400 7200 7000 6800 6600>,
			<6400 6200 6000 5800 5600 5400>,
			<5200 5000 4800 4600 4400 4200>,
			<4000 3800 3600 3400 3200 3000>,
			<2800 2600 2400 2200 2000 1800>,
			<1600 1400 1200 1000 900 800>,
			<700 600 500 400 300 200>,
			<100 0>;
		qcom,lut-data = <44170 44145 44125 44140 44080 44045>,
			<43763 43787 43835 43896 43860 43832>,
			<43383 43450 43556 43658 43638 43616>,
			<43032 43133 43287 43427 43417 43397>,
			<42707 42835 43031 43203 43196 43177>,
			<42401 42560 42776 42976 42969 42950>,
			<42095 42322 42516 42739 42732 42714>,
			<41808 42097 42256 42499 42489 42473>,
			<41589 41827 42003 42259 42248 42233>,
			<41423 41485 41755 42019 42006 41992>,
			<41261 41202 41513 41782 41768 41754>,
			<41089 41053 41277 41547 41532 41520>,
			<40902 40937 41048 41317 41301 41289>,
			<40641 40745 40830 41092 41074 41064>,
			<40227 40408 40623 40872 40854 40843>,
			<39852 40086 40417 40658 40640 40630>,
			<39642 39880 40204 40449 40432 40427>,
			<39478 39708 39989 40243 40229 40229>,
			<39269 39506 39767 40043 40035 40037>,
			<38984 39268 39532 39849 39853 39854>,
			<38741 39024 39301 39640 39657 39658>,
			<38601 38771 39076 39384 39409 39415>,
			<38497 38525 38859 39128 39148 39155>,
			<38408 38372 38676 38940 38954 38959>,
			<38330 38278 38520 38789 38805 38810>,
			<38260 38205 38383 38656 38675 38681>,
			<38194 38142 38254 38533 38553 38559>,
			<38133 38088 38139 38421 38444 38448>,
			<38072 38036 38054 38319 38342 38345>,
			<38009 37987 37991 38223 38246 38248>,
			<37948 37939 37939 38136 38159 38160>,
			<37888 37890 37893 38056 38082 38081>,
			<37831 37842 37852 37980 38010 38007>,
			<37772 37791 37809 37907 37937 37928>,
			<37714 37740 37763 37836 37864 37845>,
			<37655 37686 37713 37765 37782 37753>,
			<37591 37626 37654 37692 37680 37641>,
			<37524 37559 37587 37616 37566 37515>,
			<37452 37485 37509 37539 37471 37410>,
			<37376 37400 37412 37462 37392 37327>,
			<37293 37306 37306 37375 37309 37243>,
			<37194 37201 37193 37271 37207 37140>,
			<37085 37083 37072 37153 37090 37023>,
			<36989 36956 36945 37010 36940 36876>,
			<36899 36824 36822 36896 36848 36784>,
			<36812 36708 36716 36848 36813 36754>,
			<36769 36667 36666 36829 36796 36738>,
			<36722 36623 36608 36803 36771 36716>,
			<36660 36573 36536 36757 36733 36676>,
			<36554 36497 36416 36629 36607 36527>,
			<36336 36300 36191 36299 36250 36171>,
			<35931 35875 35801 35781 35746 35665>,
			<35333 35271 35220 35119 35087 35011>,
			<34480 34422 34416 34180 34180 34108>,
			<33115 33129 33124 32966 32881 32797>,
			<29084 29064 29039 29071 29062 29054>;
	};

	qcom,pc-temp-z1-lut {
		qcom,lut-col-legend = <0 10 25 40 50>;
		qcom,lut-row-legend = <10000 9800 9600 9400 9200>,
			<9000 8800 8600 8400 8200>,
			<8000 7800 7600 7400 7200>,
			<7000 6800 6600 6400 6200>,
			<6000 5800 5600 5400 5200>,
			<5000 4800 4600 4400 4200>,
			<4000 3800 3600 3400 3200>,
			<3000 2800 2600 2400 2200>,
			<2000 1800 1600 1400 1200>,
			<1000 900 800 700 600>,
			<500 400 300 200 100>,
			<0>;
		qcom,lut-data = <12776 12257 11779 11581 11506>,
			<12803 12304 11771 11584 11499>,
			<12813 12292 11765 11570 11490>,
			<12806 12265 11761 11561 11484>,
			<12772 12243 11758 11554 11479>,
			<12741 12222 11755 11547 11473>,
			<12728 12210 11749 11540 11467>,
			<12715 12211 11740 11534 11462>,
			<12711 12214 11733 11528 11458>,
			<12716 12216 11727 11523 11455>,
			<12723 12216 11722 11518 11452>,
			<12725 12216 11718 11513 11450>,
			<12726 12210 11715 11509 11447>,
			<12727 12196 11710 11506 11445>,
			<12732 12188 11704 11504 11443>,
			<12740 12194 11701 11503 11441>,
			<12743 12202 11702 11503 11441>,
			<12734 12202 11705 11501 11442>,
			<12726 12195 11707 11500 11443>,
			<12732 12189 11710 11500 11444>,
			<12751 12190 11713 11500 11445>,
			<12764 12194 11712 11503 11446>,
			<12756 12196 11711 11508 11447>,
			<12742 12203 11713 11512 11449>,
			<12742 12213 11719 11515 11451>,
			<12757 12225 11725 11518 11454>,
			<12771 12241 11729 11521 11458>,
			<12773 12248 11733 11525 11462>,
			<12771 12242 11735 11529 11465>,
			<12771 12235 11737 11531 11468>,
			<12778 12235 11739 11534 11470>,
			<12788 12240 11739 11537 11473>,
			<12790 12243 11737 11541 11477>,
			<12789 12235 11740 11545 11481>,
			<12787 12222 11749 11548 11483>,
			<12784 12222 11755 11552 11486>,
			<12782 12244 11756 11557 11490>,
			<12783 12263 11757 11564 11495>,
			<12802 12263 11760 11567 11499>,
			<12823 12261 11767 11568 11502>,
			<12826 12261 11772 11569 11504>,
			<12820 12267 11771 11573 11506>,
			<12825 12271 11769 11578 11508>,
			<12851 12274 11765 11580 11512>,
			<12847 12282 11770 11584 11515>,
			<12826 12261 11787 11587 11517>,
			<12826 12281 11789 11583 11516>,
			<12815 12281 11792 11591 11520>,
			<12799 12260 11791 11591 11519>,
			<12810 12258 11795 11595 11524>,
			<12848 12290 11802 11596 11527>,
			<12877 12278 11808 11607 11534>,
			<12894 12332 11824 11612 11544>,
			<12942 12374 11845 11627 11554>,
			<12942 12374 11845 11627 11554>,
			<12942 12374 11845 11627 11554>;
	};

	qcom,pc-temp-z2-lut {
		qcom,lut-col-legend = <0 10 25 40 50>;
		qcom,lut-row-legend = <10000 9800 9600 9400 9200>,
			<9000 8800 8600 8400 8200>,
			<8000 7800 7600 7400 7200>,
			<7000 6800 6600 6400 6200>,
			<6000 5800 5600 5400 5200>,
			<5000 4800 4600 4400 4200>,
			<4000 3800 3600 3400 3200>,
			<3000 2800 2600 2400 2200>,
			<2000 1800 1600 1400 1200>,
			<1000 900 800 700 600>,
			<500 400 300 200 100>,
			<0>;
		qcom,lut-data = <9039 9700 10458 11011 11011>,
			<9081 9770 10626 10713 10772>,
			<9142 10013 10732 10820 10747>,
			<9225 10339 10742 10878 10739>,
			<9363 10446 10730 10814 10753>,
			<9458 10461 10720 10731 10775>,
			<9444 10470 10707 10726 10777>,
			<9403 10476 10690 10751 10765>,
			<9395 10480 10688 10764 10756>,
			<9690 10483 10690 10729 10763>,
			<10076 10487 10690 10686 10775>,
			<10198 10490 10688 10684 10777>,
			<10245 10490 10684 10690 10775>,
			<10275 10488 10678 10690 10780>,
			<10292 10488 10666 10686 10798>,
			<10306 10488 10650 10683 10817>,
			<10339 10489 10610 10681 10817>,
			<10526 10484 10564 10682 10809>,
			<10719 10468 10556 10686 10801>,
			<10618 10450 10564 10690 10812>,
			<10156 10427 10576 10696 10826>,
			<9858 10402 10629 10717 10796>,
			<9958 10395 10695 10760 10709>,
			<10147 10400 10696 10778 10661>,
			<10206 10405 10646 10761 10658>,
			<10212 10397 10615 10743 10663>,
			<10216 10378 10623 10722 10679>,
			<10152 10370 10637 10674 10711>,
			<9967 10383 10649 10653 10732>,
			<9872 10403 10661 10650 10745>,
			<9926 10415 10672 10650 10753>,
			<10022 10424 10685 10664 10758>,
			<10117 10433 10697 10693 10773>,
			<10305 10446 10702 10716 10791>,
			<10443 10460 10707 10730 10817>,
			<10439 10467 10715 10750 10851>,
			<10410 10470 10739 10821 10903>,
			<10361 10475 10778 10929 10967>,
			<10170 10495 10815 10953 10988>,
			<9946 10527 10859 10924 10989>,
			<9873 10527 10880 10902 10986>,
			<9848 10417 10838 10920 10979>,
			<9810 10345 10797 10943 10967>,
			<9749 10339 10844 10890 10927>,
			<9584 10294 10828 10911 10925>,
			<9637 12719 10744 10941 11023>,
			<9633 14801 10783 10918 10985>,
			<9621 14920 10779 10898 10897>,
			<9591 14867 10773 10908 10994>,
			<9501 13913 10859 11050 10928>,
			<9409 13609 10805 10795 10704>,
			<9378 13530 10864 10747 10685>,
			<9330 11984 10888 10728 10667>,
			<9282 11001 10750 10685 10590>,
			<9282 11001 10750 10685 10590>,
			<9282 11001 10750 10685 10590>;
	};

	qcom,pc-temp-z3-lut {
		qcom,lut-col-legend = <0 10 25 40 50>;
		qcom,lut-row-legend = <10000 9800 9600 9400 9200>,
			<9000 8800 8600 8400 8200>,
			<8000 7800 7600 7400 7200>,
			<7000 6800 6600 6400 6200>,
			<6000 5800 5600 5400 5200>,
			<5000 4800 4600 4400 4200>,
			<4000 3800 3600 3400 3200>,
			<3000 2800 2600 2400 2200>,
			<2000 1800 1600 1400 1200>,
			<1000 900 800 700 600>,
			<500 400 300 200 100>,
			<0>;
		qcom,lut-data = <19333 19263 19336 19333 19315>,
			<19310 19263 19385 19336 19320>,
			<19292 19344 19416 19356 19331>,
			<19281 19490 19420 19366 19336>,
			<19273 19532 19420 19360 19336>,
			<19269 19531 19419 19353 19335>,
			<19270 19528 19416 19352 19333>,
			<19273 19523 19410 19352 19329>,
			<19274 19514 19404 19352 19325>,
			<19269 19506 19398 19345 19325>,
			<19262 19499 19394 19336 19325>,
			<19260 19493 19392 19336 19325>,
			<19260 19489 19391 19337 19324>,
			<19260 19485 19391 19338 19323>,
			<19260 19484 19390 19338 19319>,
			<19260 19484 19390 19337 19314>,
			<19260 19485 19386 19335 19313>,
			<19260 19485 19381 19329 19313>,
			<19259 19487 19378 19326 19314>,
			<19282 19490 19375 19324 19312>,
			<19368 19496 19375 19323 19311>,
			<19431 19507 19393 19332 19314>,
			<19501 19518 19418 19355 19326>,
			<19602 19529 19422 19364 19332>,
			<19629 19537 19422 19365 19333>,
			<19627 19535 19421 19365 19333>,
			<19621 19528 19420 19364 19333>,
			<19550 19522 19418 19361 19333>,
			<19361 19517 19416 19358 19333>,
			<19263 19512 19413 19350 19332>,
			<19262 19507 19410 19344 19330>,
			<19261 19501 19407 19343 19329>,
			<19261 19497 19404 19342 19327>,
			<19260 19492 19400 19342 19326>,
			<19259 19489 19395 19339 19325>,
			<19259 19484 19391 19337 19323>,
			<19259 19479 19390 19337 19321>,
			<19259 19475 19389 19338 19318>,
			<19260 19474 19387 19338 19317>,
			<19262 19472 19384 19335 19319>,
			<19262 19458 19380 19332 19321>,
			<19262 19325 19376 19332 19317>,
			<19262 19261 19372 19333 19313>,
			<19263 19261 19372 19334 19318>,
			<19265 19261 19364 19334 19319>,
			<19264 19258 19356 19331 19311>,
			<19264 19257 19362 19320 19311>,
			<19264 19257 19360 19320 19310>,
			<19265 19257 19346 19316 19303>,
			<19267 19257 19330 19319 19317>,
			<19269 19257 19357 19330 19326>,
			<19271 19257 19332 19331 19327>,
			<19273 19258 19323 19337 19328>,
			<19276 19258 19331 19336 19330>,
			<19276 19258 19331 19336 19330>,
			<19276 19258 19331 19336 19330>;
	};

	qcom,pc-temp-z4-lut {
		qcom,lut-col-legend = <0 10 25 40 50>;
		qcom,lut-row-legend = <10000 9800 9600 9400 9200>,
			<9000 8800 8600 8400 8200>,
			<8000 7800 7600 7400 7200>,
			<7000 6800 6600 6400 6200>,
			<6000 5800 5600 5400 5200>,
			<5000 4800 4600 4400 4200>,
			<4000 3800 3600 3400 3200>,
			<3000 2800 2600 2400 2200>,
			<2000 1800 1600 1400 1200>,
			<1000 900 800 700 600>,
			<500 400 300 200 100>,
			<0>;
		qcom,lut-data = <15516 15210 15033 14797 14763>,
			<15606 15309 15029 14877 14812>,
			<15653 15267 15019 14855 14792>,
			<15651 15172 14994 14832 14771>,
			<15593 15088 14927 14812 14763>,
			<15519 15007 14876 14794 14756>,
			<15455 14944 14858 14782 14749>,
			<15389 14915 14844 14772 14742>,
			<15339 14897 14831 14763 14734>,
			<15302 14881 14817 14756 14727>,
			<15273 14864 14804 14750 14721>,
			<15247 14850 14793 14741 14714>,
			<15224 14838 14782 14732 14708>,
			<15208 14828 14771 14723 14702>,
			<15200 14823 14758 14715 14696>,
			<15195 14827 14752 14708 14691>,
			<15188 14834 14752 14702 14684>,
			<15180 14832 14751 14697 14677>,
			<15170 14818 14749 14693 14672>,
			<15142 14808 14738 14689 14669>,
			<15064 14902 14731 14687 14667>,
			<15019 15084 14796 14707 14679>,
			<15064 15135 14890 14762 14725>,
			<15137 15069 14902 14783 14746>,
			<15147 14990 14878 14779 14745>,
			<15082 14947 14855 14774 14744>,
			<15023 14914 14842 14768 14740>,
			<15059 14894 14832 14762 14733>,
			<15175 14881 14825 14757 14727>,
			<15234 14872 14820 14752 14722>,
			<15220 14866 14817 14748 14717>,
			<15195 14862 14813 14742 14712>,
			<15175 14859 14810 14736 14706>,
			<15157 14855 14807 14730 14701>,
			<15142 14851 14802 14724 14695>,
			<15130 14845 14799 14721 14691>,
			<15121 14833 14802 14730 14699>,
			<15115 14825 14806 14748 14715>,
			<15112 14828 14806 14752 14719>,
			<15110 14838 14803 14743 14712>,
			<15106 14858 14798 14732 14704>,
			<15099 14938 14783 14722 14696>,
			<15097 14974 14768 14714 14691>,
			<15098 14974 14764 14713 14693>,
			<15080 14956 14757 14709 14691>,
			<15058 14939 14746 14705 14686>,
			<15045 14926 14726 14700 14678>,
			<15034 14905 14707 14682 14663>,
			<15023 14893 14696 14665 14650>,
			<15020 14888 14704 14664 14645>,
			<15038 14906 14697 14665 14649>,
			<15057 14911 14717 14664 14650>,
			<15074 14915 14724 14659 14650>,
			<15099 14921 14714 14660 14649>,
			<15099 14921 14714 14660 14649>,
			<15099 14921 14714 14660 14649>;
	};

	qcom,pc-temp-z5-lut {
		qcom,lut-col-legend = <0 10 25 40 50>;
		qcom,lut-row-legend = <10000 9800 9600 9400 9200>,
			<9000 8800 8600 8400 8200>,
			<8000 7800 7600 7400 7200>,
			<7000 6800 6600 6400 6200>,
			<6000 5800 5600 5400 5200>,
			<5000 4800 4600 4400 4200>,
			<4000 3800 3600 3400 3200>,
			<3000 2800 2600 2400 2200>,
			<2000 1800 1600 1400 1200>,
			<1000 900 800 700 600>,
			<500 400 300 200 100>,
			<0>;
		qcom,lut-data = <10929 11125 13247 14635 15487>,
			<11184 11550 15550 16381 17125>,
			<11347 13320 17312 18529 18985>,
			<11367 16161 18396 19499 20041>,
			<11319 17972 19222 19298 20259>,
			<11278 19220 19546 19037 20379>,
			<11302 19917 19525 19141 20309>,
			<11363 19941 19476 19649 19744>,
			<11386 19903 19359 19889 19353>,
			<11302 19885 19059 19077 19587>,
			<11194 19814 18893 18101 20042>,
			<11166 19737 19105 18167 20385>,
			<11157 19790 19531 18808 20762>,
			<11156 20012 20029 19386 20943>,
			<11183 20212 20722 20026 20228>,
			<11236 20422 21063 20533 19213>,
			<11253 20730 20307 20191 19287>,
			<11219 21195 19222 19052 20290>,
			<11182 22156 19211 18595 20981>,
			<11837 22788 20022 18911 21109>,
			<14328 22646 20517 19239 20982>,
			<16356 22239 19780 19055 20119>,
			<19019 21684 18707 18504 18052>,
			<22614 20552 18532 18305 17120>,
			<23469 19657 18611 18449 17150>,
			<22015 19786 18738 18657 17216>,
			<19789 20379 19313 18967 17450>,
			<16918 21031 20279 19436 18063>,
			<13079 21789 21118 19555 18684>,
			<11314 22559 21943 19209 19248>,
			<11269 23130 22745 18898 19837>,
			<11249 23658 23576 19306 20444>,
			<11239 24044 24329 20372 21084>,
			<11225 24320 24798 21191 21907>,
			<11215 24519 25160 21994 23310>,
			<11220 24481 25314 22480 24313>,
			<11239 24020 25208 22434 23287>,
			<11264 23661 24956 22265 20896>,
			<11316 23916 24550 21940 20239>,
			<11368 24454 23723 20961 20954>,
			<11365 23900 22877 20264 21548>,
			<11321 15904 22202 20583 20691>,
			<11309 11958 21610 20999 19310>,
			<11314 11924 21203 20623 20204>,
			<11313 11932 19659 20081 20086>,
			<11195 11784 18538 19246 17547>,
			<11153 11583 20229 17494 18089>,
			<11131 11425 21236 18827 19484>,
			<11111 11404 19670 19944 20376>,
			<11134 11423 16621 19817 23867>,
			<11165 11420 19195 19894 24566>,
			<11100 11356 15239 19841 24788>,
			<11029 11280 14318 21463 24233>,
			<10929 11179 14731 20428 23878>,
			<10929 11179 14731 20428 23878>,
			<10929 11179 14731 20428 23878>;
	};

	qcom,pc-temp-z6-lut {
		qcom,lut-col-legend = <0 10 25 40 50>;
		qcom,lut-row-legend = <10000 9800 9600 9400 9200>,
			<9000 8800 8600 8400 8200>,
			<8000 7800 7600 7400 7200>,
			<7000 6800 6600 6400 6200>,
			<6000 5800 5600 5400 5200>,
			<5000 4800 4600 4400 4200>,
			<4000 3800 3600 3400 3200>,
			<3000 2800 2600 2400 2200>,
			<2000 1800 1600 1400 1200>,
			<1000 900 800 700 600>,
			<500 400 300 200 100>,
			<0>;
		qcom,lut-data = <16331 15535 14882 14651 14598>,
			<16187 15484 14883 14682 14617>,
			<16049 15432 14881 14677 14612>,
			<15915 15377 14870 14670 14606>,
			<15778 15317 14830 14657 14602>,
			<15665 15244 14796 14642 14597>,
			<15589 15182 14780 14634 14591>,
			<15531 15150 14767 14628 14585>,
			<15490 15128 14754 14622 14579>,
			<15460 15108 14741 14614 14575>,
			<15438 15089 14730 14606 14571>,
			<15420 15072 14721 14600 14568>,
			<15405 15059 14714 14596 14564>,
			<15393 15047 14707 14592 14561>,
			<15382 15042 14700 14588 14556>,
			<15373 15041 14695 14584 14551>,
			<15367 15040 14692 14579 14547>,
			<15363 15038 14689 14574 14544>,
			<15361 15034 14685 14571 14542>,
			<15363 15030 14680 14569 14540>,
			<15374 15076 14678 14567 14539>,
			<15391 15164 14716 14582 14547>,
			<15452 15189 14772 14619 14574>,
			<15535 15170 14780 14633 14587>,
			<15556 15145 14771 14633 14587>,
			<15539 15128 14762 14631 14587>,
			<15514 15113 14757 14629 14586>,
			<15487 15104 14753 14625 14584>,
			<15456 15099 14751 14621 14581>,
			<15438 15096 14749 14616 14579>,
			<15432 15094 14747 14612 14576>,
			<15428 15093 14746 14609 14573>,
			<15426 15092 14744 14607 14571>,
			<15423 15092 14742 14605 14568>,
			<15422 15093 14739 14602 14565>,
			<15423 15093 14738 14600 14563>,
			<15428 15093 14741 14605 14566>,
			<15434 15093 14745 14615 14572>,
			<15442 15099 14746 14617 14574>,
			<15452 15112 14745 14612 14572>,
			<15461 15115 14744 14607 14570>,
			<15469 15095 14737 14604 14566>,
			<15479 15086 14732 14602 14561>,
			<15493 15097 14733 14603 14566>,
			<15505 15100 14729 14602 14566>,
			<15503 15100 14722 14600 14561>,
			<15501 15096 14718 14592 14557>,
			<15501 15091 14710 14585 14551>,
			<15503 15091 14700 14576 14541>,
			<15513 15098 14698 14578 14547>,
			<15537 15116 14712 14586 14555>,
			<15564 15130 14712 14588 14558>,
			<15597 15149 14716 14591 14560>,
			<15650 15177 14723 14594 14563>,
			<15650 15177 14723 14594 14563>,
			<15650 15177 14723 14594 14563>;
	};

	qcom,pc-temp-y1-lut {
		qcom,lut-col-legend = <(-10) 0 10 25 40 50>;
		qcom,lut-row-legend = <10000 9800 9600 9400 9200 9000>,
			<8800 8600 8400 8200 8000 7800>,
			<7600 7400 7200 7000 6800 6600>,
			<6400 6200 6000 5800 5600 5400>,
			<5200 5000 4800 4600 4400 4200>,
			<4000 3800 3600 3400 3200 3000>,
			<2800 2600 2400 2200 2000 1800>,
			<1600 1400 1200 1000 900 800>,
			<700 600 500 400 300 200>,
			<100 0>;
		qcom,lut-data = <6386 5843 5567 5281 5181 5118>,
			<6372 5845 5569 5293 5177 5120>,
			<6357 5850 5574 5300 5172 5121>,
			<6344 5855 5579 5303 5168 5120>,
			<6335 5859 5583 5304 5164 5119>,
			<6331 5861 5584 5304 5161 5117>,
			<6332 5862 5584 5300 5157 5114>,
			<6336 5862 5583 5294 5154 5109>,
			<6336 5862 5583 5289 5151 5106>,
			<6331 5862 5586 5281 5149 5104>,
			<6328 5863 5587 5275 5147 5103>,
			<6331 5868 5580 5274 5144 5102>,
			<6337 5876 5571 5274 5141 5101>,
			<6335 5878 5569 5272 5139 5100>,
			<6314 5876 5569 5268 5136 5099>,
			<6297 5875 5570 5266 5134 5098>,
			<6315 5876 5570 5263 5132 5097>,
			<6352 5877 5571 5260 5131 5096>,
			<6368 5878 5571 5259 5130 5095>,
			<6367 5880 5572 5258 5130 5094>,
			<6360 5881 5573 5257 5130 5093>,
			<6345 5882 5573 5259 5129 5093>,
			<6323 5883 5573 5261 5128 5093>,
			<6310 5881 5574 5261 5128 5093>,
			<6307 5873 5579 5260 5129 5094>,
			<6308 5867 5583 5259 5130 5094>,
			<6316 5870 5583 5258 5133 5095>,
			<6329 5879 5584 5257 5135 5095>,
			<6332 5881 5583 5258 5136 5096>,
			<6328 5881 5579 5263 5137 5098>,
			<6324 5880 5576 5268 5137 5100>,
			<6325 5880 5577 5271 5139 5101>,
			<6329 5879 5579 5273 5143 5102>,
			<6329 5879 5583 5275 5146 5103>,
			<6324 5882 5590 5277 5148 5105>,
			<6315 5884 5596 5279 5150 5107>,
			<6303 5880 5596 5281 5153 5109>,
			<6283 5874 5593 5282 5157 5111>,
			<6278 5871 5589 5282 5158 5113>,
			<6308 5872 5583 5281 5158 5115>,
			<6339 5874 5579 5280 5158 5116>,
			<6328 5871 5579 5285 5160 5118>,
			<6299 5866 5583 5291 5163 5121>,
			<6300 5866 5582 5301 5168 5123>,
			<6300 5866 5579 5304 5171 5126>,
			<6285 5871 5584 5306 5172 5127>,
			<6291 5872 5597 5309 5176 5128>,
			<6299 5855 5595 5312 5175 5128>,
			<6300 5863 5590 5310 5174 5131>,
			<6304 5872 5591 5314 5178 5133>,
			<6296 5881 5594 5321 5182 5134>,
			<6311 5894 5599 5334 5192 5138>,
			<6329 5907 5612 5341 5196 5145>,
			<6411 5922 5632 5361 5208 5153>,
			<6411 5922 5632 5361 5208 5153>,
			<6411 5922 5632 5361 5208 5153>;
	};

	qcom,pc-temp-y2-lut {
		qcom,lut-col-legend = <(-10) 0 10 25 40 50>;
		qcom,lut-row-legend = <10000 9800 9600 9400 9200 9000>,
			<8800 8600 8400 8200 8000 7800>,
			<7600 7400 7200 7000 6800 6600>,
			<6400 6200 6000 5800 5600 5400>,
			<5200 5000 4800 4600 4400 4200>,
			<4000 3800 3600 3400 3200 3000>,
			<2800 2600 2400 2200 2000 1800>,
			<1600 1400 1200 1000 900 800>,
			<700 600 500 400 300 200>,
			<100 0>;
		qcom,lut-data = <9656 9697 10352 11287 11444 11724>,
			<9656 9682 10418 11235 11428 11649>,
			<9657 9675 10513 11186 11391 11574>,
			<9657 9675 10613 11143 11348 11503>,
			<9657 9681 10696 11113 11311 11443>,
			<9657 9694 10741 11100 11293 11398>,
			<9657 9880 10756 11106 11283 11365>,
			<9657 10174 10764 11118 11266 11341>,
			<9657 10192 10762 11119 11251 11331>,
			<9657 9899 10745 11112 11236 11331>,
			<9657 9688 10732 11109 11226 11329>,
			<9657 9950 10754 11116 11219 11289>,
			<9657 10416 10810 11125 11211 11230>,
			<9657 10468 10881 11129 11203 11225>,
			<9657 10030 11001 11132 11192 11275>,
			<9656 9692 11076 11137 11187 11319>,
			<9656 9682 11077 11174 11200 11330>,
			<9656 9679 11077 11228 11233 11337>,
			<9656 9676 11068 11254 11298 11366>,
			<9656 9673 11001 11272 11457 11464>,
			<9656 9671 10946 11279 11555 11541>,
			<9656 9670 10942 11289 11518 11554>,
			<9656 9670 10942 11307 11457 11558>,
			<9656 9669 10906 11323 11449 11557>,
			<9656 9668 10628 11347 11476 11553>,
			<9656 9666 10392 11370 11499 11553>,
			<9656 9664 10378 11399 11510 11568>,
			<9656 9663 10364 11428 11526 11596>,
			<9655 9661 10299 11440 11552 11631>,
			<9655 9660 10184 11448 11604 11686>,
			<9655 9659 10059 11454 11646 11729>,
			<9655 9658 9937 11453 11672 11746>,
			<9655 9658 9819 11449 11704 11756>,
			<9655 9657 9763 11452 11732 11763>,
			<9655 9656 9739 11462 11781 11816>,
			<9655 9656 9723 11467 11811 11857>,
			<9655 9656 9708 11467 11779 11830>,
			<9655 9655 9695 11467 11720 11775>,
			<9655 9655 9686 11459 11696 11748>,
			<9655 9655 9679 11427 11692 11754>,
			<9655 9655 9673 11395 11693 11758>,
			<9655 9654 9668 11370 11676 11705>,
			<9655 9654 9664 11336 11656 11626>,
			<9655 9654 9661 11287 11686 11626>,
			<9655 9654 9659 11135 11658 11634>,
			<9655 9654 9657 11054 11562 11606>,
			<9655 9654 9657 11089 11482 11525>,
			<9654 9654 9657 11076 11466 11425>,
			<9654 9653 9656 11063 11365 11358>,
			<9654 9653 9656 10992 11398 11359>,
			<9654 9653 9655 10887 11313 11325>,
			<9653 9653 9654 10784 11234 11276>,
			<9652 9652 9654 10700 11093 11219>,
			<9650 9651 9653 10623 10986 11035>,
			<9650 9651 9653 10623 10986 11035>,
			<9650 9651 9653 10623 10986 11035>;
	};

	qcom,pc-temp-y3-lut {
		qcom,lut-col-legend = <(-10) 0 10 25 40 50>;
		qcom,lut-row-legend = <10000 9800 9600 9400 9200 9000>,
			<8800 8600 8400 8200 8000 7800>,
			<7600 7400 7200 7000 6800 6600>,
			<6400 6200 6000 5800 5600 5400>,
			<5200 5000 4800 4600 4400 4200>,
			<4000 3800 3600 3400 3200 3000>,
			<2800 2600 2400 2200 2000 1800>,
			<1600 1400 1200 1000 900 800>,
			<700 600 500 400 300 200>,
			<100 0>;
		qcom,lut-data = <14774 13909 13433 13294 13275 13272>,
			<14689 13862 13429 13295 13275 13272>,
			<14602 13809 13425 13295 13276 13273>,
			<14515 13758 13421 13296 13276 13273>,
			<14427 13715 13418 13297 13277 13273>,
			<14339 13687 13416 13298 13277 13273>,
			<14244 13673 13414 13299 13277 13273>,
			<14151 13664 13413 13300 13277 13274>,
			<14077 13639 13411 13300 13277 13275>,
			<14009 13578 13407 13300 13278 13275>,
			<13974 13528 13404 13300 13278 13275>,
			<13974 13509 13405 13301 13278 13275>,
			<13976 13497 13407 13301 13279 13275>,
			<13969 13497 13406 13301 13279 13275>,
			<13913 13516 13392 13302 13281 13275>,
			<13869 13530 13378 13302 13282 13275>,
			<13873 13526 13371 13304 13282 13276>,
			<13882 13515 13364 13305 13283 13278>,
			<13882 13502 13357 13305 13284 13280>,
			<13864 13481 13347 13303 13286 13282>,
			<13848 13459 13338 13300 13288 13282>,
			<13859 13434 13332 13294 13284 13279>,
			<13888 13410 13326 13289 13278 13274>,
			<13918 13405 13318 13288 13276 13272>,
			<13949 13421 13304 13288 13275 13271>,
			<13985 13444 13292 13287 13275 13271>,
			<14026 13472 13280 13286 13275 13271>,
			<14072 13508 13265 13285 13275 13272>,
			<14117 13545 13260 13285 13275 13272>,
			<14161 13585 13261 13285 13274 13271>,
			<14205 13629 13262 13284 13273 13271>,
			<14253 13678 13265 13284 13274 13271>,
			<14303 13734 13271 13284 13276 13271>,
			<14357 13795 13279 13283 13276 13271>,
			<14414 13863 13294 13283 13276 13271>,
			<14473 13937 13309 13282 13276 13271>,
			<14530 14017 13320 13281 13275 13271>,
			<14587 14102 13333 13280 13273 13270>,
			<14643 14190 13350 13279 13273 13270>,
			<14698 14281 13372 13279 13273 13270>,
			<14754 14373 13403 13279 13273 13270>,
			<14813 14467 13449 13282 13274 13271>,
			<14875 14563 13518 13285 13274 13272>,
			<14954 14658 13610 13287 13273 13272>,
			<15048 14747 13732 13288 13273 13272>,
			<15133 14808 13832 13289 13275 13273>,
			<15180 14836 13858 13293 13277 13274>,
			<15307 14918 13929 13298 13277 13275>,
			<15443 15007 14012 13305 13282 13278>,
			<15611 15111 14102 13308 13283 13277>,
			<15835 15237 14211 13309 13280 13277>,
			<16246 15419 14365 13314 13281 13277>,
			<17517 15778 14608 13325 13283 13278>,
			<20434 16778 15010 13344 13287 13280>,
			<20434 16778 15010 13344 13287 13280>,
			<20434 16778 15010 13344 13287 13280>;
	};

	qcom,pc-temp-y4-lut {
		qcom,lut-col-legend = <(-10) 0 10 25 40 50>;
		qcom,lut-row-legend = <10000 9800 9600 9400 9200 9000>,
			<8800 8600 8400 8200 8000 7800>,
			<7600 7400 7200 7000 6800 6600>,
			<6400 6200 6000 5800 5600 5400>,
			<5200 5000 4800 4600 4400 4200>,
			<4000 3800 3600 3400 3200 3000>,
			<2800 2600 2400 2200 2000 1800>,
			<1600 1400 1200 1000 900 800>,
			<700 600 500 400 300 200>,
			<100 0>;
		qcom,lut-data = <18159 17323 16898 16562 16475 16455>,
			<18172 17567 17001 16567 16473 16455>,
			<18176 17730 17102 16570 16472 16454>,
			<18174 17829 17188 16572 16471 16454>,
			<18168 17877 17248 16572 16471 16453>,
			<18158 17891 17272 16572 16470 16453>,
			<18140 17831 17256 16568 16470 16452>,
			<18120 17732 17224 16560 16471 16452>,
			<18136 17717 17198 16556 16471 16452>,
			<18264 17774 17174 16553 16473 16453>,
			<18357 17844 17157 16552 16476 16454>,
			<18329 17914 17145 16554 16479 16457>,
			<18248 17980 17136 16559 16483 16461>,
			<18103 17961 17143 16565 16487 16465>,
			<17733 17721 17205 16574 16493 16470>,
			<17427 17518 17252 16586 16499 16477>,
			<17350 17491 17237 16608 16509 16482>,
			<17303 17476 17197 16638 16521 16489>,
			<17210 17434 17148 16673 16541 16501>,
			<16994 17294 17076 16718 16577 16529>,
			<16832 17121 16990 16738 16598 16547>,
			<16810 16934 16882 16656 16558 16521>,
			<16798 16745 16765 16543 16489 16472>,
			<16797 16693 16709 16511 16469 16455>,
			<16801 16689 16682 16498 16463 16452>,
			<16808 16688 16664 16494 16461 16451>,
			<16814 16690 16642 16495 16462 16452>,
			<16820 16699 16620 16497 16464 16453>,
			<16828 16708 16615 16500 16466 16455>,
			<16843 16720 16622 16506 16472 16459>,
			<16859 16734 16633 16513 16478 16464>,
			<16872 16747 16644 16520 16487 16472>,
			<16885 16762 16658 16526 16496 16481>,
			<16898 16777 16674 16525 16500 16483>,
			<16909 16793 16691 16520 16501 16479>,
			<16922 16809 16708 16514 16502 16474>,
			<16936 16823 16726 16497 16488 16465>,
			<16951 16836 16745 16482 16464 16454>,
			<16962 16848 16757 16481 16457 16451>,
			<16971 16862 16764 16483 16457 16451>,
			<16976 16873 16771 16486 16457 16450>,
			<16971 16877 16783 16491 16456 16449>,
			<16958 16879 16802 16498 16454 16446>,
			<16961 16896 16840 16506 16452 16440>,
			<16978 16915 16920 16512 16453 16438>,
			<17011 16917 17011 16527 16463 16449>,
			<17019 16921 17041 16547 16469 16455>,
			<17067 16974 17157 16575 16480 16467>,
			<17125 17035 17293 16622 16508 16506>,
			<17175 17093 17421 16650 16520 16485>,
			<17177 17103 17487 16640 16478 16459>,
			<17182 17052 17488 16641 16488 16464>,
			<17487 17062 17494 16709 16517 16487>,
			<18679 17356 17611 16825 16601 16558>,
			<18679 17356 17611 16825 16601 16558>,
			<18679 17356 17611 16825 16601 16558>;
	};

	qcom,pc-temp-y5-lut {
		qcom,lut-col-legend = <(-10) 0 10 25 40 50>;
		qcom,lut-row-legend = <10000 9800 9600 9400 9200 9000>,
			<8800 8600 8400 8200 8000 7800>,
			<7600 7400 7200 7000 6800 6600>,
			<6400 6200 6000 5800 5600 5400>,
			<5200 5000 4800 4600 4400 4200>,
			<4000 3800 3600 3400 3200 3000>,
			<2800 2600 2400 2200 2000 1800>,
			<1600 1400 1200 1000 900 800>,
			<700 600 500 400 300 200>,
			<100 0>;
		qcom,lut-data = <9358 12792 12363 17084 17521 19635>,
			<9995 11669 12851 16751 17459 19425>,
			<10657 11190 13326 16575 17336 19103>,
			<11248 11198 13774 16507 17160 18743>,
			<11677 11534 14183 16502 16940 18419>,
			<11849 12042 14540 16510 16681 18207>,
			<11726 13132 14890 16615 16216 18083>,
			<11521 14434 15184 16761 15649 17957>,
			<11524 14407 15288 16704 15347 17783>,
			<11917 12547 15332 16375 15186 17397>,
			<12541 11202 15350 16035 15022 16970>,
			<13952 12295 15023 15744 14748 16578>,
			<15764 14245 14455 15444 14486 16139>,
			<15949 14634 14336 15150 14489 15628>,
			<14250 14014 14460 14747 14763 14930>,
			<12937 13538 14626 14521 14947 14529>,
			<13878 13901 14817 14494 14759 14822>,
			<15713 14729 15089 14524 14456 15465>,
			<15950 15370 15466 14760 14550 15977>,
			<13766 15942 16127 15551 15486 16411>,
			<11815 16261 16587 16338 16389 16805>,
			<11477 15034 16639 16916 16909 17156>,
			<11296 12476 16665 17462 17334 17484>,
			<11221 11507 16565 18070 17544 17805>,
			<11180 11291 15605 18760 17767 18188>,
			<11162 11197 14683 19044 17889 18435>,
			<11223 11263 13672 18564 17829 18389>,
			<11360 11429 11932 17900 17684 18180>,
			<11396 11545 11311 17664 17403 17910>,
			<11291 11617 11199 17525 16575 17327>,
			<11195 11674 11147 17469 16032 16781>,
			<11210 11718 11311 17483 16460 16486>,
			<11271 11753 11705 17542 17359 16258>,
			<11343 11799 11943 17754 18124 16286>,
			<11466 11906 12110 18223 18911 17061>,
			<11569 11998 12213 18423 19323 17847>,
			<11569 12000 12264 17862 18894 18150>,
			<11529 11962 12365 17031 18158 18355>,
			<11532 11912 12365 16429 17999 18340>,
			<11614 11822 12251 15778 18059 18214>,
			<11686 11739 12157 15562 18152 18126>,
			<11580 11714 12182 16562 18180 18295>,
			<11319 11696 12239 17166 18112 18756>,
			<11253 11603 12198 16826 17712 20259>,
			<11194 11491 12129 16397 17521 20666>,
			<11058 11476 12337 15744 16594 17887>,
			<11086 11546 12615 15787 16586 17738>,
			<11194 11601 12625 15913 15873 17826>,
			<11295 11844 12712 16209 17647 17962>,
			<11388 12292 12902 16143 17561 18883>,
			<11392 12252 12974 16444 18465 20599>,
			<11007 11706 12722 16669 17971 20547>,
			<10333 11339 11928 16494 17869 19763>,
			<9626 10556 11041 16418 17765 18861>,
			<9626 10556 11041 16418 17765 18861>,
			<9626 10556 11041 16418 17765 18861>;
	};

	qcom,pc-temp-y6-lut {
		qcom,lut-col-legend = <(-10) 0 10 25 40 50>;
		qcom,lut-row-legend = <10000 9800 9600 9400 9200 9000>,
			<8800 8600 8400 8200 8000 7800>,
			<7600 7400 7200 7000 6800 6600>,
			<6400 6200 6000 5800 5600 5400>,
			<5200 5000 4800 4600 4400 4200>,
			<4000 3800 3600 3400 3200 3000>,
			<2800 2600 2400 2200 2000 1800>,
			<1600 1400 1200 1000 900 800>,
			<700 600 500 400 300 200>,
			<100 0>;
		qcom,lut-data = <7480 6435 5657 5125 5021 5005>,
			<7403 6401 5673 5123 5021 5005>,
			<7327 6368 5678 5120 5021 5005>,
			<7252 6338 5676 5117 5021 5004>,
			<7179 6312 5668 5114 5020 5004>,
			<7107 6290 5657 5110 5020 5004>,
			<7024 6276 5639 5106 5019 5004>,
			<6949 6263 5616 5101 5019 5004>,
			<6921 6234 5596 5097 5019 5004>,
			<6911 6163 5576 5094 5019 5004>,
			<6901 6117 5560 5091 5019 5004>,
			<6886 6139 5547 5091 5020 5005>,
			<6864 6180 5536 5090 5021 5006>,
			<6815 6179 5534 5090 5022 5007>,
			<6674 6094 5535 5092 5024 5008>,
			<6563 6021 5535 5094 5027 5010>,
			<6543 6010 5528 5100 5030 5012>,
			<6533 6004 5509 5109 5033 5015>,
			<6507 5989 5488 5118 5039 5020>,
			<6435 5948 5460 5128 5051 5029>,
			<6383 5899 5428 5132 5058 5035>,
			<6388 5846 5394 5105 5044 5025>,
			<6403 5795 5359 5068 5019 5006>,
			<6422 5784 5338 5058 5012 5000>,
			<6447 5805 5326 5055 5010 4999>,
			<6476 5837 5317 5054 5009 4999>,
			<6506 5869 5309 5054 5009 4999>,
			<6540 5908 5302 5054 5010 5000>,
			<6574 5949 5301 5055 5011 5000>,
			<6609 5992 5312 5057 5012 5001>,
			<6645 6038 5328 5060 5014 5003>,
			<6684 6087 5346 5063 5017 5005>,
			<6726 6140 5371 5065 5021 5008>,
			<6768 6196 5397 5065 5023 5008>,
			<6812 6257 5427 5064 5023 5007>,
			<6857 6320 5460 5063 5024 5006>,
			<6901 6385 5497 5059 5019 5004>,
			<6946 6451 5538 5055 5012 5001>,
			<6991 6519 5584 5055 5010 5000>,
			<7038 6591 5634 5057 5010 5000>,
			<7085 6664 5691 5059 5011 5000>,
			<7127 6735 5762 5065 5011 5000>,
			<7168 6806 5851 5071 5011 5000>,
			<7226 6880 5958 5077 5011 4999>,
			<7303 6955 6094 5084 5012 4999>,
			<7383 7008 6204 5091 5016 5003>,
			<7421 7028 6237 5102 5020 5006>,
			<7526 7103 6330 5116 5023 5010>,
			<7644 7186 6435 5138 5035 5023>,
			<7789 7283 6544 5152 5039 5017>,
			<7956 7380 6652 5154 5026 5010>,
			<8285 7501 6776 5163 5031 5012>,
			<9394 7784 6965 5204 5042 5020>,
			<11923 8614 7306 5264 5071 5043>,
			<11923 8614 7306 5264 5071 5043>,
			<11923 8614 7306 5264 5071 5043>;
	};

};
